VERSION "0"

NS_ :

BS_:

BU_: VCU_BeagleBone MCLeft MCRight DCU PDU BMU VCU_F7 WSBFL WSBFR WSBRL WSBRR ChargeCart
VAL_TABLE_ Vt_On_Off 1 "On" 0 "Off" ;
VAL_TABLE_ DC_Channel 4 "CHANNEL_ON_FUSE_BLOWN" 3 "CHANNEL_OFF_FUSE_BLOWN" 2 "CHANNEL_ON" 1 "CHANNEL_OFF" 0 "INVALID" ;
VAL_TABLE_ Contactor 4 "CONTACTOR_FAULT_CLOSED" 3 "CONTACTOR_FAULT_OPEN" 2 "CONTACTOR_CLOSED" 1 "CONTACTOR_OPEN" 0 "INVALID" ;
VAL_TABLE_ DCDC_State 3 "Error" 2 "On" 1 "Off" 0 "Invalid" ;
VAL_TABLE_ BMS_State 7 "Failure_Fatal" 6 "Charging" 5 "Discharge" 4 "Precharge" 3 "HV_Enable" 2 "HV_Disable" 1 "Wait_System_Up" 0 "Self_Check" ;

BO_ 3221225472 VECTOR__INDEPENDENT_SIG_MSG: 0 Vector__XXX
 SG_ Hartbeat_BMU : 0|8@1+ (1,0) [0|0] "" Vector__XXX
 SG_ Hartbeat_VCU_F7 : 0|8@1+ (1,0) [0|0] "" Vector__XXX
 SG_ Hartbeat_DCU : 0|8@1+ (1,0) [0|0] "" Vector__XXX
 SG_ Hartbeat_PDU : 0|8@1+ (1,0) [0|0] "" Vector__XXX
 SG_ Hartbeat_WSBFL : 0|8@1+ (1,0) [0|0] "" Vector__XXX
 SG_ Hartbeat_WSBFR : 0|8@1+ (1,0) [0|0] "" Vector__XXX
 SG_ Hartbeat_WSBRL : 0|8@1+ (1,0) [0|0] "" Vector__XXX
 SG_ Hartbeat_WSBRR : 0|8@1+ (1,0) [0|0] "" Vector__XXX
 SG_ Hartbeat_ChargeCart : 0|8@1+ (1,0) [0|0] "" Vector__XXX
 SG_ StateContactorPositive : 0|3@1- (1,0) [0|0] "" Vector__XXX
 SG_ StateContactorNegative : 0|3@1- (1,0) [0|0] "" Vector__XXX
 SG_ PRO_CAN_CRC : 0|8@1- (1,0) [0|0] "" Vector__XXX
 SG_ PRO_CAN_COUNT : 0|4@1- (1,0) [0|0] "" Vector__XXX
 SG_ PRO_CAN_RES : 0|4@1- (1,0) [0|0] "" Vector__XXX
 SG_ VoltageHVBusInverterRight : 0|16@1+ (1,0) [0|0] "" Vector__XXX
 SG_ CurrentHVBusInverterRight : 0|16@1+ (1,0) [0|0] "" Vector__XXX
 SG_ PRO_CAN_CRC : 0|8@1- (1,0) [0|0] "" Vector__XXX
 SG_ PRO_CAN_COUNT : 0|4@1- (1,0) [0|0] "" Vector__XXX
 SG_ PRO_CAN_RES : 0|4@1- (1,0) [0|0] "" Vector__XXX
 SG_ VoltageHVBusInverterLeft : 0|16@1+ (1,0) [0|0] "" Vector__XXX
 SG_ CurrentHVBusInverterLeft : 0|16@1+ (1,0) [0|0] "" Vector__XXX
 SG_ VoltageBatteryLV : 0|14@1+ (1,0) [0|16383] "mV" Vector__XXX

BO_ 2287209474 VCU_EM_Fault: 8 VCU_F7
 SG_ EMFaultEvent : 0|8@1+ (1,0) [0|255] ""  VCU_BeagleBone

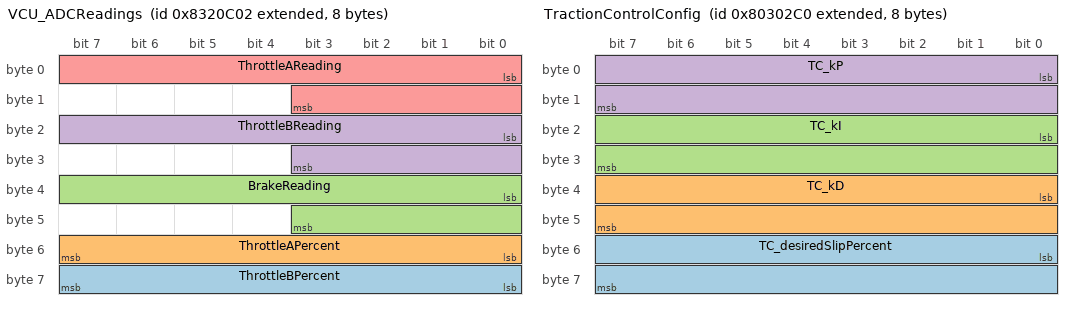
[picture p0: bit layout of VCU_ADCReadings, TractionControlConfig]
BO_ 2284981250 VCU_ADCReadings: 8 VCU_F7
 SG_ ThrottleBPercent : 56|8@1+ (0.5,0) [0|127.5] "" Vector__XXX
 SG_ ThrottleAPercent : 48|8@1+ (0.5,0) [0|127.5] "" Vector__XXX
 SG_ BrakeReading : 32|12@1+ (1,0) [0|4095] ""  VCU_BeagleBone
 SG_ ThrottleBReading : 16|12@1+ (1,0) [0|4095] ""  VCU_BeagleBone
 SG_ ThrottleAReading : 0|12@1+ (1,0) [0|4095] ""  VCU_BeagleBone

BO_ 2281898688 TractionControlConfig: 8 VCU_BeagleBone
 SG_ TC_desiredSlipPercent : 48|16@1- (0.0001,0) [-3.2768|3.2767] "percent"  VCU_F7
 SG_ TC_kD : 32|16@1+ (0.01,0) [0|655.35] ""  VCU_F7
 SG_ TC_kI : 16|16@1+ (0.01,0) [0|655.35] ""  VCU_F7
 SG_ TC_kP : 0|16@1+ (0.01,0) [0|655.35] ""  VCU_F7

BO_ 2291796994 RearWheelSpeedRADS: 8 VCU_F7
 SG_ VCU_wheelSpeed_RR : 32|32@1+ (1E-005,0) [0|42949.67295] "rads/s" Vector__XXX
 SG_ VCU_wheelSpeed_RL : 0|32@1+ (1E-005,0) [0|42949.67295] "rads/s" Vector__XXX

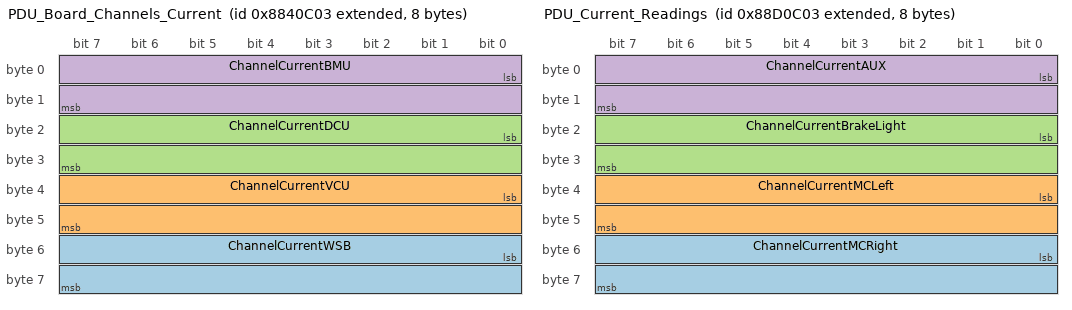
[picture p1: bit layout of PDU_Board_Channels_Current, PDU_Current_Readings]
BO_ 2290355203 PDU_Board_Channels_Current: 8 PDU
 SG_ ChannelCurrentWSB : 48|16@1+ (0.01,0) [0|0] "Amps"  VCU_BeagleBone
 SG_ ChannelCurrentVCU : 32|16@1+ (0.01,0) [0|0] "Amps"  VCU_BeagleBone
 SG_ ChannelCurrentDCU : 16|16@1+ (0.01,0) [0|0] "Amps"  VCU_BeagleBone
 SG_ ChannelCurrentBMU : 0|16@1+ (0.01,0) [0|0] "Amps"  VCU_BeagleBone

BO_ 2290945027 PDU_Current_Readings: 8 PDU
 SG_ ChannelCurrentMCRight : 48|16@1+ (0.01,0) [0|0] "Amps"  VCU_BeagleBone
 SG_ ChannelCurrentMCLeft : 32|16@1+ (0.01,0) [0|0] "Amps"  VCU_BeagleBone
 SG_ ChannelCurrentBrakeLight : 16|16@1+ (0.01,0) [0|0] "Amps"  VCU_BeagleBone
 SG_ ChannelCurrentAUX : 0|16@1+ (0.01,0) [0|0] ""  VCU_BeagleBone

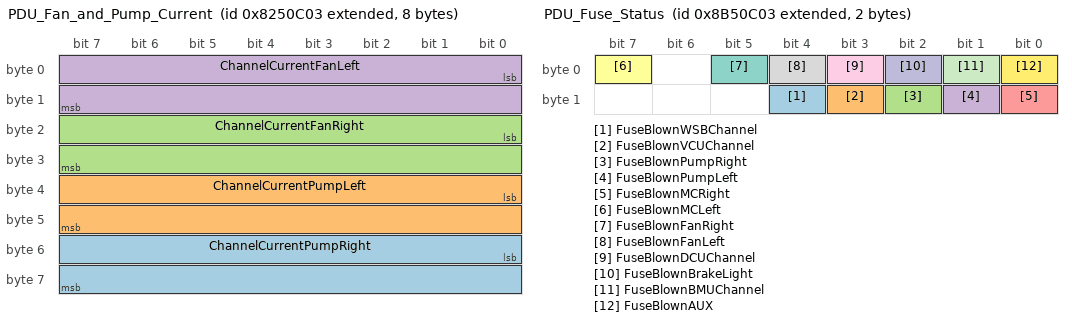
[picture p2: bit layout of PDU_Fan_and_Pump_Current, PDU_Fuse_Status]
BO_ 2284129283 PDU_Fan_and_Pump_Current: 8 PDU
 SG_ ChannelCurrentPumpRight : 48|16@1+ (0.01,0) [0|0] "Amps"  VCU_BeagleBone
 SG_ ChannelCurrentPumpLeft : 32|16@1+ (0.01,0) [0|0] "Amps"  VCU_BeagleBone
 SG_ ChannelCurrentFanRight : 16|16@1+ (0.01,0) [0|0] "Amps"  VCU_BeagleBone
 SG_ ChannelCurrentFanLeft : 0|16@1+ (0.01,0) [0|0] "Amps"  VCU_BeagleBone

BO_ 2293566467 PDU_Fuse_Status: 2 PDU
 SG_ FuseBlownWSBChannel : 12|1@1+ (1,0) [0|0] ""  VCU_BeagleBone
 SG_ FuseBlownVCUChannel : 11|1@1+ (1,0) [0|0] ""  VCU_BeagleBone
 SG_ FuseBlownPumpRight : 10|1@1+ (1,0) [0|0] ""  VCU_BeagleBone
 SG_ FuseBlownPumpLeft : 9|1@1+ (1,0) [0|0] ""  VCU_BeagleBone
 SG_ FuseBlownMCRight : 8|1@1+ (1,0) [0|0] ""  VCU_BeagleBone
 SG_ FuseBlownMCLeft : 7|1@1+ (1,0) [0|0] ""  VCU_BeagleBone
 SG_ FuseBlownFanRight : 5|1@1+ (1,0) [0|0] ""  VCU_BeagleBone
 SG_ FuseBlownFanLeft : 4|1@1+ (1,0) [0|0] ""  VCU_BeagleBone
 SG_ FuseBlownDCUChannel : 3|1@1+ (1,0) [0|0] ""  VCU_BeagleBone
 SG_ FuseBlownBrakeLight : 2|1@1+ (1,0) [0|0] ""  VCU_BeagleBone
 SG_ FuseBlownBMUChannel : 1|1@1+ (1,0) [0|0] ""  VCU_BeagleBone
 SG_ FuseBlownAUX : 0|1@1+ (1,0) [0|0] ""  VCU_BeagleBone

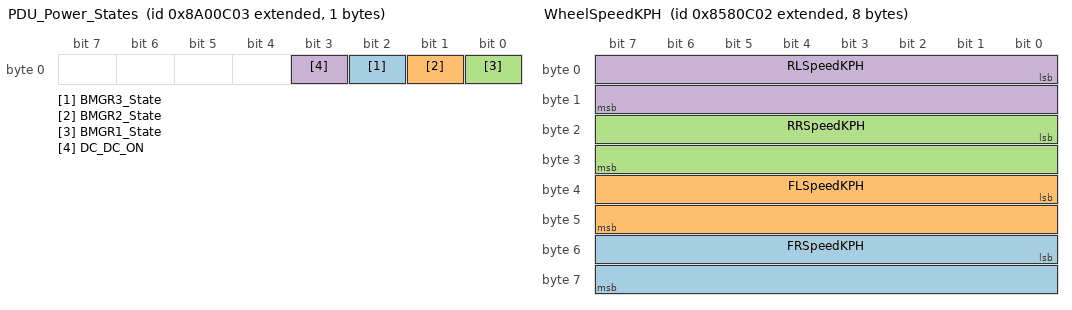
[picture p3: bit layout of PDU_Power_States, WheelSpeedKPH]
BO_ 2292190211 PDU_Power_States: 1 PDU
 SG_ BMGR3_State : 2|1@1+ (1,0) [0|0] ""  VCU_BeagleBone
 SG_ BMGR2_State : 1|1@1+ (1,0) [0|0] ""  VCU_BeagleBone
 SG_ BMGR1_State : 0|1@1+ (1,0) [0|0] ""  VCU_BeagleBone
 SG_ DC_DC_ON : 3|1@1+ (1,0) [0|0] ""  VCU_BeagleBone

BO_ 2287471618 WheelSpeedKPH: 8 VCU_F7
 SG_ FRSpeedKPH : 48|16@1- (0.04,0) [-1310.72|1310.68] "km/h" Vector__XXX
 SG_ FLSpeedKPH : 32|16@1- (0.04,0) [-1310.72|1310.68] "km/h" Vector__XXX
 SG_ RRSpeedKPH : 16|16@1- (0.04,0) [-1310.72|1310.68] "kph"  VCU_BeagleBone
 SG_ RLSpeedKPH : 0|16@1- (0.04,0) [-1310.72|1310.68] "kph"  VCU_BeagleBone

BO_ 2214986495 UartOverCanRx: 4 PDU
 SG_ UartOverCanRX : 0|32@1- (1,0) [0|4294967295] ""  VCU_BeagleBone

BO_ 2215051010 UartOverCanTx: 1 VCU_BeagleBone
 SG_ UartOverCanTX : 0|8@1- (1,0) [0|0] ""  VCU_F7,WSBRR,WSBRL,WSBFR,WSBFL,BMU,DCU,PDU

BO_ 2214985474 UartOverCanConfig: 1 VCU_BeagleBone
 SG_ UartOverCanConfigSignal : 0|8@1- (1,0) [0|0] ""  VCU_F7,WSBRR,WSBRL,WSBFR,WSBFL,PDU,DCU,BMU

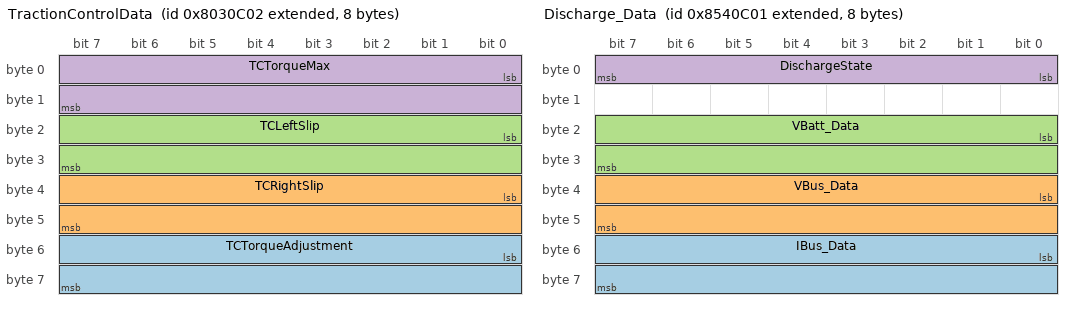
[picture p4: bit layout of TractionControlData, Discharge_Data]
BO_ 2281901058 TractionControlData: 8 VCU_F7
 SG_ TCTorqueAdjustment : 48|16@1- (0.01,0) [-327.68|327.67] "" Vector__XXX
 SG_ TCRightSlip : 32|16@1- (0.003,0) [-98.304|98.301] "percent" Vector__XXX
 SG_ TCLeftSlip : 16|16@1- (0.003,0) [-98.304|98.301] "percent" Vector__XXX
 SG_ TCTorqueMax : 0|16@1+ (0.001,0) [0|65.535] "Nm"  VCU_BeagleBone

BO_ 2215641611 WSBRR_Sensors: 8 WSBRR
 SG_ RR_WheelDistance : 0|32@1+ (1,0) [0|4294967295] "mm"  VCU_BeagleBone

BO_ 2215641610 WSBRL_Sensors: 8 WSBRL
 SG_ RL_WheelDistance : 0|32@1+ (1,0) [0|4294967295] "mm"  VCU_BeagleBone

BO_ 2215641609 WSBFR_Sensors: 8 WSBFR
 SG_ FR_WheelDistance : 0|32@1+ (1,0) [0|4294967295] "mm"  VCU_BeagleBone
 SG_ FR_Speed_RAD_S : 32|16@1- (0.0625,0) [0|4095.9375] "rad/s"  VCU_F7,VCU_BeagleBone

BO_ 2215641608 WSBFL_Sensors: 8 WSBFL
 SG_ FL_WheelDistance : 0|32@1+ (1,0) [0|4294967295] "mm"  VCU_BeagleBone
 SG_ FL_Speed_RAD_S : 32|16@1- (0.0625,0) [-2048|2047.9375] "rad/s"  VCU_F7,VCU_BeagleBone

BO_ 2281835521 BMU_BatteryChecks: 8 BMU
 SG_ BatteryTaskFailure : 0|8@1+ (1,0) [0|0] "" Vector__XXX

BO_ 2281769985 BMU_AmsVBatt: 8 BMU
 SG_ AMS_PackVoltage : 0|16@1+ (0.01,0) [0|655.35] ""  VCU_BeagleBone

BO_ 2282884097 BMU_FanPeriod: 8 BMU
 SG_ FanPeriod : 0|8@1- (1,0) [0|0] ""  VCU_BeagleBone

BO_ 2295598081 PrechargeState: 8 BMU
 SG_ PrechargeState : 0|8@1+ (1,0) [0|0] ""  VCU_BeagleBone

BO_ 2287209473 Discharge_Data: 8 BMU
 SG_ IBus_Data : 48|16@1- (1,0) [0|0] "" Vector__XXX
 SG_ VBus_Data : 32|16@1+ (1,0) [0|0] "" Vector__XXX
 SG_ VBatt_Data : 16|16@1+ (0.01,0) [0|655.35] "" Vector__XXX
 SG_ DischargeState : 0|8@1+ (1,0) [0|0] ""  VCU_BeagleBone

BO_ 2297236481 BMU_Interlock_Loop_Status: 8 BMU
 SG_ BMU_checkFailed : 0|8@1+ (1,0) [0|0] ""  VCU_BeagleBone

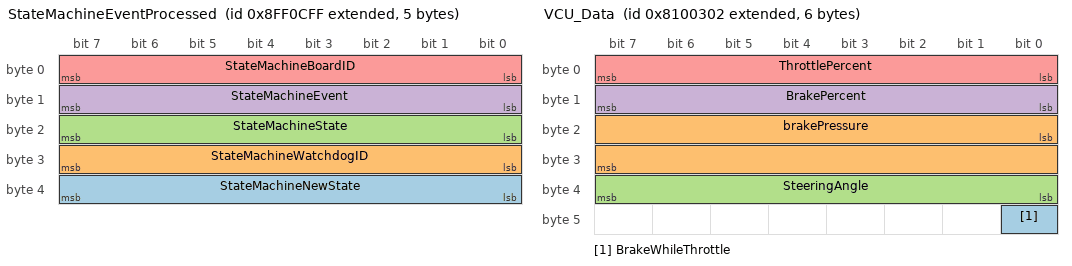
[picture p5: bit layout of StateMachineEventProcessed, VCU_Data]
BO_ 2298416383 StateMachineEventProcessed: 5 VCU_F7
 SG_ StateMachineNewState : 32|8@1+ (1,0) [0|0] "" Vector__XXX
 SG_ StateMachineWatchdogID : 24|8@1- (1,0) [0|0] ""  VCU_BeagleBone
 SG_ StateMachineState : 16|8@1- (1,0) [0|0] ""  VCU_BeagleBone
 SG_ StateMachineEvent : 8|8@1- (1,0) [0|0] ""  VCU_BeagleBone
 SG_ StateMachineBoardID : 0|8@1- (1,0) [0|0] ""  VCU_BeagleBone

BO_ 2147548939 WSBRL_DTC: 6 WSBRL
 SG_ DTC_Severity : 8|8@1- (1,0) [1|4] ""  WSBRR,WSBFR,WSBFL
 SG_ DTC_Data : 16|32@1- (1,0) [0|0] ""  WSBRR,WSBFR,WSBFL
 SG_ DTC_CODE : 0|8@1+ (1,0) [0|0] ""  WSBRR,WSBFR,WSBFL

BO_ 2147548938 WSBRR_DTC: 6 WSBRR
 SG_ DTC_Severity : 8|8@1- (1,0) [1|4] ""  WSBRL,WSBFR,WSBFL
 SG_ DTC_Data : 16|32@1- (1,0) [0|0] ""  WSBRL,WSBFR,WSBFL
 SG_ DTC_CODE : 0|8@1+ (1,0) [0|0] ""  WSBRL,WSBFR,WSBFL

BO_ 2147548937 WSBFR_DTC: 6 WSBFR
 SG_ DTC_Severity : 8|8@1- (1,0) [1|4] ""  WSBRR,WSBRL,WSBFL
 SG_ DTC_Data : 16|32@1- (1,0) [0|0] ""  WSBRR,WSBRL,WSBFL
 SG_ DTC_CODE : 0|8@1+ (1,0) [0|0] ""  WSBRR,WSBRL,WSBFL

BO_ 2147548936 WSBFL_DTC: 6 WSBFL
 SG_ DTC_Severity : 8|8@1- (1,0) [1|4] ""  WSBFR,WSBRR,WSBRL
 SG_ DTC_Data : 16|32@1- (1,0) [0|0] ""  WSBFR,WSBRR,WSBRL
 SG_ DTC_CODE : 0|8@1+ (1,0) [0|0] ""  WSBFR,WSBRR,WSBRL

BO_ 2226717697 BMU_ChargeEN_State: 8 BMU
 SG_ ChargeEN_State : 0|1@1+ (1,0) [0|0] ""  ChargeCart

BO_ 2227830532 ChargeCart_Heartbeat: 8 ChargeCart
 SG_ ChargeCart_Heartbeat_dummydata : 0|1@1- (1,0) [0|0] ""  BMU

BO_ 2551190019 LV_Bus_Measurements: 4 PDU
 SG_ CurrentBusLV : 16|16@1+ (1,0) [0|0] "mA" Vector__XXX
 SG_ VoltageBusLV : 0|14@1+ (1,0) [0|16383] "mV" Vector__XXX

BO_ 2282750722 VCU_Data: 6 VCU_F7
 SG_ BrakeWhileThrottle : 40|1@1+ (1,0) [0|1] ""  VCU_BeagleBone
 SG_ brakePressure : 16|16@1- (1,0) [0|0] ""  VCU_BeagleBone
 SG_ SteeringAngle : 32|8@1- (1,0) [0|0] "degrees" Vector__XXX
 SG_ BrakePercent : 8|8@1+ (1,0) [0|0] "percent"  PDU
 SG_ ThrottlePercent : 0|8@1+ (1,0) [0|0] "percent" Vector__XXX

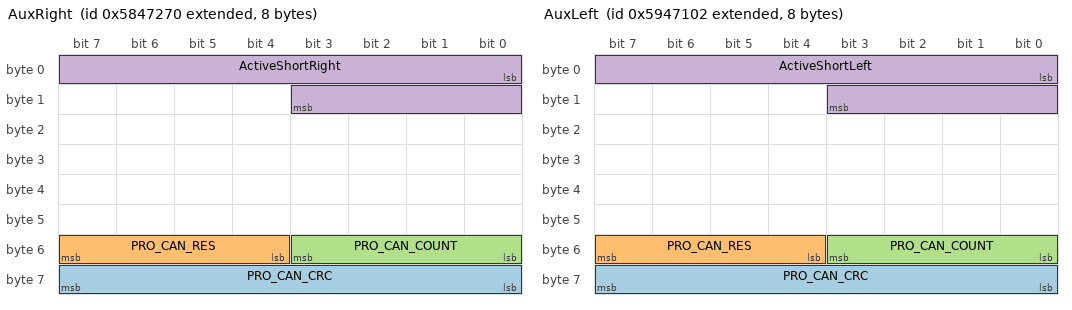
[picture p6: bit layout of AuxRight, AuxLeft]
BO_ 2240049776 AuxRight: 8 VCU_F7
 SG_ PRO_CAN_CRC : 56|8@1+ (1,0) [0|0] "" Vector__XXX
 SG_ PRO_CAN_RES : 52|4@1+ (1,0) [0|0] "" Vector__XXX
 SG_ PRO_CAN_COUNT : 48|4@1+ (1,0) [0|0] "" Vector__XXX
 SG_ ActiveShortRight : 0|12@1+ (1,0) [0|0] "" Vector__XXX

BO_ 2241097986 AuxLeft: 8 VCU_F7
 SG_ PRO_CAN_CRC : 56|8@1+ (1,0) [0|0] "" Vector__XXX
 SG_ PRO_CAN_RES : 52|4@1+ (1,0) [0|0] "" Vector__XXX
 SG_ PRO_CAN_COUNT : 48|4@1+ (1,0) [0|0] "" Vector__XXX
 SG_ ActiveShortLeft : 0|12@1+ (1,0) [0|0] "" Vector__XXX

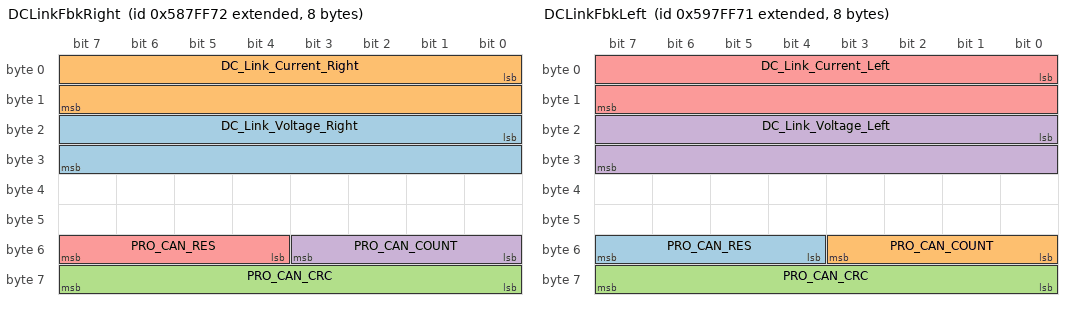
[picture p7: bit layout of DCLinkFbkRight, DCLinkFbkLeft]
BO_ 2240282482 DCLinkFbkRight: 8 MCRight
 SG_ DC_Link_Voltage_Right : 16|16@1+ (0.0625,0) [0|4095.9375] "V"  VCU_F7
 SG_ DC_Link_Current_Right : 0|16@1+ (0.0625,-128) [-128|3967.9375] "A"  VCU_F7
 SG_ PRO_CAN_CRC : 56|8@1+ (1,0) [0|0] "" Vector__XXX
 SG_ PRO_CAN_COUNT : 48|4@1+ (1,0) [0|0] "" Vector__XXX
 SG_ PRO_CAN_RES : 52|4@1+ (1,0) [0|0] "" Vector__XXX

BO_ 2241331057 DCLinkFbkLeft: 8 MCLeft
 SG_ PRO_CAN_RES : 52|4@1+ (1,0) [0|0] "" Vector__XXX
 SG_ PRO_CAN_COUNT : 48|4@1+ (1,0) [0|0] "" Vector__XXX
 SG_ PRO_CAN_CRC : 56|8@1+ (1,0) [0|0] "" Vector__XXX
 SG_ DC_Link_Voltage_Left : 16|16@1+ (0.0625,0) [0|4095.9375] "V"  VCU_F7
 SG_ DC_Link_Current_Left : 0|16@1+ (0.0625,-128) [-128|3967.9375] "A"  VCU_F7

BO_ 2214987522 VCU_EM_State: 1 VCU_F7
 SG_ EM_State : 0|1@1+ (1,0) [0|0] ""  DCU

BO_ 2214919943 DCU_Heartbeat: 1 DCU
 SG_ DCU_Heartbeat_dummydata : 0|1@1- (1,0) [0|0] ""  VCU_F7,PDU,BMU

BO_ 2214919939 PDU_Heartbeat: 1 PDU
 SG_ PDU_Heartbeat_dummydata : 0|1@1- (1,0) [0|0] ""  VCU_F7,DCU,BMU

BO_ 2214919938 VCU_F7_Heartbeat: 1 VCU_F7
 SG_ VCU_Heartbeat_dummydata : 0|1@1- (1,0) [0|0] ""  PDU,DCU,BMU

BO_ 2214919937 BMU_Heartbeat: 1 BMU
 SG_ BMU_Heartbeat_dummydata : 0|1@1- (1,0) [0|0] ""  ChargeCart,VCU_F7,PDU,DCU

BO_ 2282689025 BMU_BrakePressure: 4 BMU
 SG_ BrakePressureBMU : 0|32@1+ (0.1,0) [0|0] ""  VCU_BeagleBone

BO_ 2217082625 BMU_HV_Power_State: 1 BMU
 SG_ HV_Power_State : 0|1@1+ (1,0) [0|0] ""  ChargeCart,DCU,VCU_BeagleBone,VCU_F7,PDU

BO_ 2214855426 VCU_EM_Power_State_Request: 1 VCU_F7
 SG_ EM_Power_State_Request : 0|1@1+ (1,0) [0|0] ""  PDU

BO_ 2147548931 PDU_DTC: 6 PDU
 SG_ DTC_Severity : 8|8@1- (1,0) [1|4] ""  WSBRR,WSBRL,WSBFR,WSBFL,VCU_F7,VCU_BeagleBone,DCU,ChargeCart,BMU
 SG_ DTC_Data : 16|32@1- (1,0) [0|0] ""  WSBRR,WSBRL,WSBFR,WSBFL,VCU_F7,VCU_BeagleBone,DCU,ChargeCart,BMU
 SG_ DTC_CODE : 0|8@1+ (1,0) [0|0] ""  WSBRR,WSBRL,WSBFR,WSBFL,VCU_F7,VCU_BeagleBone,DCU,ChargeCart,BMU

BO_ 2147548935 DCU_DTC: 6 DCU
 SG_ DTC_Severity : 8|8@1- (1,0) [1|4] ""  WSBRR,WSBRL,WSBFR,WSBFL,VCU_BeagleBone,VCU_F7,PDU,ChargeCart,BMU
 SG_ DTC_Data : 16|32@1- (1,0) [0|0] ""  WSBRR,WSBRL,WSBFR,WSBFL,VCU_BeagleBone,VCU_F7,PDU,ChargeCart,BMU
 SG_ DTC_CODE : 0|8@1+ (1,0) [0|0] ""  WSBRR,WSBRL,WSBFR,WSBFL,VCU_BeagleBone,VCU_F7,PDU,ChargeCart,BMU

BO_ 2147548930 VCU_F7_DTC: 6 VCU_F7
 SG_ DTC_Severity : 8|8@1- (1,0) [1|4] ""  WSBRR,WSBRL,WSBFR,WSBFL,VCU_BeagleBone,PDU,DCU,ChargeCart,BMU
 SG_ DTC_CODE : 0|8@1+ (1,0) [0|0] ""  WSBRR,WSBRL,WSBFR,WSBFL,VCU_BeagleBone,PDU,DCU,ChargeCart,BMU
 SG_ DTC_Data : 16|32@1- (1,0) [0|0] ""  WSBRR,WSBRL,WSBFR,WSBFL,VCU_BeagleBone,PDU,DCU,ChargeCart,BMU

BO_ 2147548929 BMU_DTC: 6 BMU
 SG_ DTC_Severity : 8|8@1- (1,0) [1|4] ""  WSBRR,WSBRL,WSBFR,WSBFL,VCU_BeagleBone,VCU_F7,PDU,DCU,ChargeCart
 SG_ DTC_Data : 16|32@1- (1,0) [0|0] ""  WSBRR,WSBRL,WSBFR,WSBFL,VCU_BeagleBone,VCU_F7,PDU,DCU,ChargeCart
 SG_ DTC_CODE : 0|8@1+ (1,0) [0|0] ""  WSBRR,WSBRL,WSBFR,WSBFL,VCU_BeagleBone,VCU_F7,PDU,DCU,ChargeCart

BO_ 2147548932 ChargeCart_DTC: 6 ChargeCart
 SG_ DTC_Severity : 8|8@1- (1,0) [1|4] ""  WSBRR,WSBRL,WSBFR,WSBFL,VCU_BeagleBone,VCU_F7,PDU,DCU,BMU
 SG_ DTC_Data : 16|32@1- (1,0) [0|0] ""  WSBRR,WSBRL,WSBFR,WSBFL,VCU_BeagleBone,VCU_F7,PDU,DCU,BMU
 SG_ DTC_CODE : 0|8@1+ (1,0) [0|0] ""  WSBRR,WSBRL,WSBFR,WSBFL,VCU_BeagleBone,VCU_F7,PDU,DCU,BMU

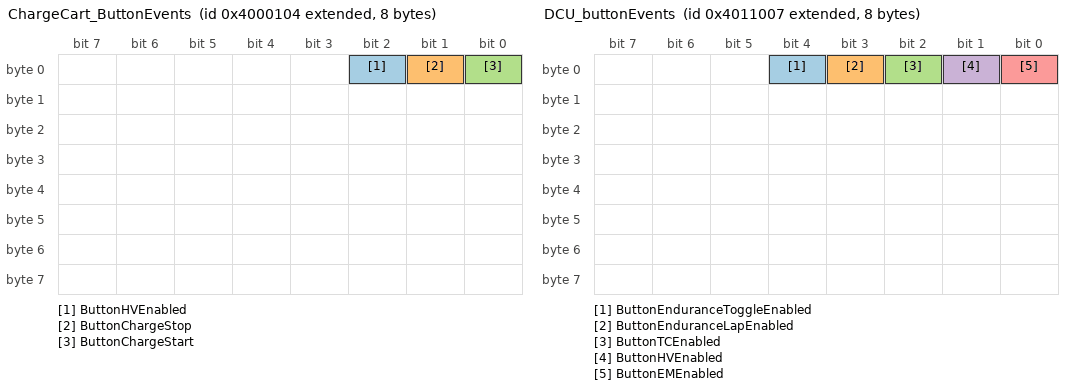
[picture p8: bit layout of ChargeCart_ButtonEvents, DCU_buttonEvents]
BO_ 2214592772 ChargeCart_ButtonEvents: 8 ChargeCart
 SG_ ButtonHVEnabled : 2|1@1- (1,0) [0|0] "bool"  BMU
 SG_ ButtonChargeStop : 1|1@1- (1,0) [0|0] "bool"  BMU,VCU_BeagleBone
 SG_ ButtonChargeStart : 0|1@1- (1,0) [0|0] "bool"  BMU,VCU_BeagleBone

BO_ 2558526465 BMU_CellVoltage: 8 BMU
 SG_ VoltageCellMuxSelect M : 0|8@1+ (1,0) [0|256] ""  ChargeCart,VCU_BeagleBone
 SG_ VoltageCell01 m0 : 8|16@1+ (0.0001,0) [0|6.5535] "V"  ChargeCart,VCU_BeagleBone
 SG_ VoltageCell02 m0 : 24|16@1+ (0.0001,0) [0|6.5535] "V"  ChargeCart,VCU_BeagleBone
 SG_ VoltageCell03 m0 : 40|16@1+ (0.0001,0) [0|6.5535] "V"  ChargeCart,VCU_BeagleBone
 SG_ VoltageCell04 m1 : 8|16@1+ (0.0001,0) [0|6.5535] "V"  ChargeCart,VCU_BeagleBone
 SG_ VoltageCell05 m1 : 24|16@1+ (0.0001,0) [0|6.5535] "V"  ChargeCart,VCU_BeagleBone
 SG_ VoltageCell06 m1 : 40|16@1+ (0.0001,0) [0|6.5535] "V"  ChargeCart,VCU_BeagleBone
 SG_ VoltageCell07 m2 : 8|16@1+ (0.0001,0) [0|6.5535] "V"  ChargeCart,VCU_BeagleBone
 SG_ VoltageCell08 m2 : 24|16@1+ (0.0001,0) [0|6.5535] "V"  ChargeCart,VCU_BeagleBone
 SG_ VoltageCell09 m2 : 40|16@1+ (0.0001,0) [0|6.5535] "V"  ChargeCart,VCU_BeagleBone
 SG_ VoltageCell10 m3 : 8|16@1+ (0.0001,0) [0|6.5535] "V"  ChargeCart,VCU_BeagleBone
 SG_ VoltageCell11 m3 : 24|16@1+ (0.0001,0) [0|6.5535] "V"  ChargeCart,VCU_BeagleBone
 SG_ VoltageCell12 m3 : 40|16@1+ (0.0001,0) [0|6.5535] "V"  ChargeCart,VCU_BeagleBone
 SG_ VoltageCell13 m4 : 8|16@1+ (0.0001,0) [0|6.5535] "V"  ChargeCart,VCU_BeagleBone
 SG_ VoltageCell14 m4 : 24|16@1+ (0.0001,0) [0|6.5535] "V"  ChargeCart,VCU_BeagleBone
 SG_ VoltageCell15 m4 : 40|16@1+ (0.0001,0) [0|6.5535] "V"  ChargeCart,VCU_BeagleBone
 SG_ VoltageCell16 m5 : 8|16@1+ (0.0001,0) [0|6.5535] "V"  ChargeCart,VCU_BeagleBone
 SG_ VoltageCell17 m5 : 24|16@1+ (0.0001,0) [0|6.5535] "V"  ChargeCart,VCU_BeagleBone
 SG_ VoltageCell18 m5 : 40|16@1+ (0.0001,0) [0|6.5535] "V"  ChargeCart,VCU_BeagleBone
 SG_ VoltageCell19 m6 : 8|16@1+ (0.0001,0) [0|6.5535] "V"  ChargeCart,VCU_BeagleBone
 SG_ VoltageCell20 m6 : 24|16@1+ (0.0001,0) [0|6.5535] "V"  ChargeCart,VCU_BeagleBone
 SG_ VoltageCell21 m6 : 40|16@1+ (0.0001,0) [0|6.5535] "V"  ChargeCart,VCU_BeagleBone
 SG_ VoltageCell22 m7 : 8|16@1+ (0.0001,0) [0|6.5535] "V"  ChargeCart,VCU_BeagleBone
 SG_ VoltageCell23 m7 : 24|16@1+ (0.0001,0) [0|6.5535] "V"  ChargeCart,VCU_BeagleBone
 SG_ VoltageCell24 m7 : 40|16@1+ (0.0001,0) [0|6.5535] "V"  ChargeCart,VCU_BeagleBone
 SG_ VoltageCell25 m8 : 8|16@1+ (0.0001,0) [0|6.5535] "V"  ChargeCart,VCU_BeagleBone
 SG_ VoltageCell26 m8 : 24|16@1+ (0.0001,0) [0|6.5535] "V"  ChargeCart,VCU_BeagleBone
 SG_ VoltageCell27 m8 : 40|16@1+ (0.0001,0) [0|6.5535] "V"  ChargeCart,VCU_BeagleBone
 SG_ VoltageCell28 m9 : 8|16@1+ (0.0001,0) [0|6.5535] "V"  ChargeCart,VCU_BeagleBone
 SG_ VoltageCell29 m9 : 24|16@1+ (0.0001,0) [0|6.5535] "V"  ChargeCart,VCU_BeagleBone
 SG_ VoltageCell30 m9 : 40|16@1+ (0.0001,0) [0|6.5535] "V"  ChargeCart,VCU_BeagleBone
 SG_ VoltageCell31 m10 : 8|16@1+ (0.0001,0) [0|6.5535] "V"  ChargeCart,VCU_BeagleBone
 SG_ VoltageCell32 m10 : 24|16@1+ (0.0001,0) [0|6.5535] "V"  ChargeCart,VCU_BeagleBone
 SG_ VoltageCell33 m10 : 40|16@1+ (0.0001,0) [0|6.5535] "V"  ChargeCart,VCU_BeagleBone
 SG_ VoltageCell34 m11 : 8|16@1+ (0.0001,0) [0|6.5535] "V"  ChargeCart,VCU_BeagleBone
 SG_ VoltageCell35 m11 : 24|16@1+ (0.0001,0) [0|6.5535] "V"  ChargeCart,VCU_BeagleBone
 SG_ VoltageCell36 m11 : 40|16@1+ (0.0001,0) [0|6.5535] "V"  ChargeCart,VCU_BeagleBone
 SG_ VoltageCell37 m12 : 8|16@1+ (0.0001,0) [0|6.5535] "V"  ChargeCart,VCU_BeagleBone
 SG_ VoltageCell38 m12 : 24|16@1+ (0.0001,0) [0|6.5535] "V"  ChargeCart,VCU_BeagleBone
 SG_ VoltageCell39 m12 : 40|16@1+ (0.0001,0) [0|6.5535] "V"  ChargeCart,VCU_BeagleBone
 SG_ VoltageCell40 m13 : 8|16@1+ (0.0001,0) [0|6.5535] "V"  ChargeCart,VCU_BeagleBone
 SG_ VoltageCell41 m13 : 24|16@1+ (0.0001,0) [0|6.5535] "V"  ChargeCart,VCU_BeagleBone
 SG_ VoltageCell42 m13 : 40|16@1+ (0.0001,0) [0|6.5535] "V"  ChargeCart,VCU_BeagleBone
 SG_ VoltageCell43 m14 : 8|16@1+ (0.0001,0) [0|6.5535] "V"  ChargeCart,VCU_BeagleBone
 SG_ VoltageCell44 m14 : 24|16@1+ (0.0001,0) [0|6.5535] "V"  ChargeCart,VCU_BeagleBone
 SG_ VoltageCell45 m14 : 40|16@1+ (0.0001,0) [0|6.5535] "V"  ChargeCart,VCU_BeagleBone
 SG_ VoltageCell46 m15 : 8|16@1+ (0.0001,0) [0|6.5535] "V"  ChargeCart,VCU_BeagleBone
 SG_ VoltageCell47 m15 : 24|16@1+ (0.0001,0) [0|6.5535] "V"  ChargeCart,VCU_BeagleBone
 SG_ VoltageCell48 m15 : 40|16@1+ (0.0001,0) [0|6.5535] "V"  ChargeCart,VCU_BeagleBone
 SG_ VoltageCell49 m16 : 8|16@1+ (0.0001,0) [0|6.5535] "V"  ChargeCart,VCU_BeagleBone
 SG_ VoltageCell50 m16 : 24|16@1+ (0.0001,0) [0|6.5535] "V"  ChargeCart,VCU_BeagleBone
 SG_ VoltageCell51 m16 : 40|16@1+ (0.0001,0) [0|6.5535] "V"  ChargeCart,VCU_BeagleBone
 SG_ VoltageCell52 m17 : 8|16@1+ (0.0001,0) [0|6.5535] "V"  ChargeCart,VCU_BeagleBone
 SG_ VoltageCell53 m17 : 24|16@1+ (0.0001,0) [0|6.5535] "V"  ChargeCart,VCU_BeagleBone
 SG_ VoltageCell54 m17 : 40|16@1+ (0.0001,0) [0|6.5535] "V"  ChargeCart,VCU_BeagleBone
 SG_ VoltageCell55 m18 : 8|16@1+ (0.0001,0) [0|6.5535] "V"  ChargeCart,VCU_BeagleBone
 SG_ VoltageCell56 m18 : 24|16@1+ (0.0001,0) [0|6.5535] "V"  ChargeCart,VCU_BeagleBone
 SG_ VoltageCell57 m18 : 40|16@1+ (0.0001,0) [0|6.5535] "V"  ChargeCart,VCU_BeagleBone
 SG_ VoltageCell58 m19 : 8|16@1+ (0.0001,0) [0|6.5535] "V"  ChargeCart,VCU_BeagleBone
 SG_ VoltageCell59 m19 : 24|16@1+ (0.0001,0) [0|6.5535] "V"  ChargeCart,VCU_BeagleBone
 SG_ VoltageCell60 m19 : 40|16@1+ (0.0001,0) [0|6.5535] "V"  ChargeCart,VCU_BeagleBone
 SG_ VoltageCell61 m20 : 8|16@1+ (0.0001,0) [0|6.5535] "V"  VCU_BeagleBone,ChargeCart
 SG_ VoltageCell62 m20 : 24|16@1+ (0.0001,0) [0|6.5535] "V"  VCU_BeagleBone,ChargeCart
 SG_ VoltageCell63 m20 : 40|16@1+ (0.0001,0) [0|6.5535] "V"  VCU_BeagleBone,ChargeCart
 SG_ VoltageCell64 m21 : 8|16@1+ (0.0001,0) [0|6.5535] "V"  VCU_BeagleBone,ChargeCart
 SG_ VoltageCell65 m21 : 24|16@1+ (0.0001,0) [0|6.5535] "V"  VCU_BeagleBone,ChargeCart
 SG_ VoltageCell66 m21 : 40|16@1+ (0.0001,0) [0|6.5535] "V"  VCU_BeagleBone,ChargeCart
 SG_ VoltageCell67 m22 : 8|16@1+ (0.0001,0) [0|6.5535] "V"  VCU_BeagleBone,ChargeCart
 SG_ VoltageCell68 m22 : 24|16@1+ (0.0001,0) [0|6.5535] "V"  VCU_BeagleBone,ChargeCart
 SG_ VoltageCell69 m22 : 40|16@1+ (0.0001,0) [0|6.5535] "V"  VCU_BeagleBone,ChargeCart
 SG_ VoltageCell70 m23 : 8|16@1+ (0.0001,0) [0|6.5535] "V"  VCU_BeagleBone,ChargeCart
 SG_ VoltageCell71 m23 : 24|16@1+ (0.0001,0) [0|6.5535] "V"  VCU_BeagleBone,ChargeCart
 SG_ VoltageCell72 m23 : 40|16@1+ (0.0001,0) [0|6.5535] "V"  VCU_BeagleBone,ChargeCart
 SG_ VoltageCell73 m24 : 8|16@1+ (0.0001,0) [0|6.5535] "V"  VCU_BeagleBone,ChargeCart
 SG_ VoltageCell74 m24 : 24|16@1+ (0.0001,0) [0|6.5535] "V"  VCU_BeagleBone,ChargeCart
 SG_ VoltageCell75 m24 : 40|16@1+ (0.0001,0) [0|6.5535] "V"  VCU_BeagleBone,ChargeCart
 SG_ VoltageCell76 m25 : 8|16@1+ (0.0001,0) [0|6.5535] "V"  VCU_BeagleBone,ChargeCart
 SG_ VoltageCell77 m25 : 24|16@1+ (0.0001,0) [0|6.5535] "V"  VCU_BeagleBone,ChargeCart
 SG_ VoltageCell78 m25 : 40|16@1+ (0.0001,0) [0|6.5535] "V"  VCU_BeagleBone,ChargeCart
 SG_ VoltageCell79 m26 : 8|16@1+ (0.0001,0) [0|6.5535] "V"  VCU_BeagleBone,ChargeCart
 SG_ VoltageCell80 m26 : 24|16@1+ (0.0001,0) [0|6.5535] "V"  VCU_BeagleBone,ChargeCart
 SG_ VoltageCell81 m26 : 40|16@1+ (0.0001,0) [0|6.5535] "V"  VCU_BeagleBone,ChargeCart
 SG_ VoltageCell82 m27 : 8|16@1+ (0.0001,0) [0|6.5535] "V"  VCU_BeagleBone,ChargeCart
 SG_ VoltageCell83 m27 : 24|16@1+ (0.0001,0) [0|6.5535] "V"  VCU_BeagleBone,ChargeCart
 SG_ VoltageCell84 m27 : 40|16@1+ (0.0001,0) [0|6.5535] "V"  VCU_BeagleBone,ChargeCart
 SG_ VoltageCell85 m28 : 8|16@1+ (0.0001,0) [0|6.5535] "V"  VCU_BeagleBone,ChargeCart
 SG_ VoltageCell86 m28 : 24|16@1+ (0.0001,0) [0|6.5535] "V"  VCU_BeagleBone,ChargeCart
 SG_ VoltageCell87 m28 : 40|16@1+ (0.0001,0) [0|6.5535] "V"  VCU_BeagleBone,ChargeCart
 SG_ VoltageCell88 m29 : 8|16@1+ (0.0001,0) [0|6.5535] "V"  VCU_BeagleBone,ChargeCart
 SG_ VoltageCell89 m29 : 24|16@1+ (0.0001,0) [0|6.5535] "V"  VCU_BeagleBone,ChargeCart
 SG_ VoltageCell90 m29 : 40|16@1+ (0.0001,0) [0|6.5535] "V"  VCU_BeagleBone,ChargeCart
 SG_ VoltageCell91 m30 : 8|16@1+ (0.0001,0) [0|6.5535] "V"  VCU_BeagleBone,ChargeCart
 SG_ VoltageCell92 m30 : 24|16@1+ (0.0001,0) [0|6.5535] "V"  VCU_BeagleBone,ChargeCart
 SG_ VoltageCell93 m30 : 40|16@1+ (0.0001,0) [0|6.5535] "V"  VCU_BeagleBone,ChargeCart
 SG_ VoltageCell94 m31 : 8|16@1+ (0.0001,0) [0|6.5535] "V"  VCU_BeagleBone,ChargeCart
 SG_ VoltageCell95 m31 : 24|16@1+ (0.0001,0) [0|6.5535] "V"  VCU_BeagleBone,ChargeCart
 SG_ VoltageCell96 m31 : 40|16@1+ (0.0001,0) [0|6.5535] "V"  VCU_BeagleBone,ChargeCart
 SG_ VoltageCell97 m32 : 8|16@1+ (0.0001,0) [0|6.5535] "V"  VCU_BeagleBone,ChargeCart
 SG_ VoltageCell98 m32 : 24|16@1+ (0.0001,0) [0|6.5535] "V"  VCU_BeagleBone,ChargeCart
 SG_ VoltageCell99 m32 : 40|16@1+ (0.0001,0) [0|6.5535] "V"  VCU_BeagleBone,ChargeCart
 SG_ VoltageCell100 m33 : 8|16@1+ (0.0001,0) [0|6.5535] "V"  VCU_BeagleBone,ChargeCart
 SG_ VoltageCell101 m33 : 24|16@1+ (0.0001,0) [0|6.5535] "V"  VCU_BeagleBone,ChargeCart
 SG_ VoltageCell102 m33 : 40|16@1+ (0.0001,0) [0|6.5535] "V"  VCU_BeagleBone,ChargeCart
 SG_ VoltageCell103 m34 : 8|16@1+ (0.0001,0) [0|6.5535] "V"  VCU_BeagleBone,ChargeCart
 SG_ VoltageCell104 m34 : 24|16@1+ (0.0001,0) [0|6.5535] "V"  VCU_BeagleBone,ChargeCart
 SG_ VoltageCell105 m34 : 40|16@1+ (0.0001,0) [0|6.5535] "V"  VCU_BeagleBone,ChargeCart
 SG_ VoltageCell106 m35 : 8|16@1+ (0.0001,0) [0|6.5535] "V"  VCU_BeagleBone,ChargeCart
 SG_ VoltageCell107 m35 : 24|16@1+ (0.0001,0) [0|6.5535] "V"  VCU_BeagleBone,ChargeCart
 SG_ VoltageCell108 m35 : 40|16@1+ (0.0001,0) [0|6.5535] "V"  VCU_BeagleBone,ChargeCart
 SG_ VoltageCell109 m36 : 8|16@1+ (0.0001,0) [0|6.5535] "V"  VCU_BeagleBone,ChargeCart
 SG_ VoltageCell110 m36 : 24|16@1+ (0.0001,0) [0|6.5535] "V"  VCU_BeagleBone,ChargeCart
 SG_ VoltageCell111 m36 : 40|16@1+ (0.0001,0) [0|6.5535] "V"  VCU_BeagleBone,ChargeCart
 SG_ VoltageCell112 m37 : 8|16@1+ (0.0001,0) [0|6.5535] "V"  VCU_BeagleBone,ChargeCart
 SG_ VoltageCell113 m37 : 24|16@1+ (0.0001,0) [0|6.5535] "V"  VCU_BeagleBone,ChargeCart
 SG_ VoltageCell114 m37 : 40|16@1+ (0.0001,0) [0|6.5535] "V"  VCU_BeagleBone,ChargeCart
 SG_ VoltageCell115 m38 : 8|16@1+ (0.0001,0) [0|6.5535] "V"  VCU_BeagleBone,ChargeCart
 SG_ VoltageCell116 m38 : 24|16@1+ (0.0001,0) [0|6.5535] "V"  VCU_BeagleBone,ChargeCart
 SG_ VoltageCell117 m38 : 40|16@1+ (0.0001,0) [0|6.5535] "V"  VCU_BeagleBone,ChargeCart
 SG_ VoltageCell118 m39 : 8|16@1+ (0.0001,0) [0|6.5535] "V"  VCU_BeagleBone,ChargeCart
 SG_ VoltageCell119 m39 : 24|16@1+ (0.0001,0) [0|6.5535] "V"  VCU_BeagleBone,ChargeCart
 SG_ VoltageCell120 m39 : 40|16@1+ (0.0001,0) [0|6.5535] "V"  VCU_BeagleBone,ChargeCart
 SG_ VoltageCell121 m40 : 8|16@1+ (0.0001,0) [0|6.5535] "V"  VCU_BeagleBone,ChargeCart
 SG_ VoltageCell122 m40 : 24|16@1+ (0.0001,0) [0|6.5535] "V"  VCU_BeagleBone,ChargeCart
 SG_ VoltageCell123 m40 : 40|16@1+ (0.0001,0) [0|6.5535] "V"  VCU_BeagleBone,ChargeCart
 SG_ VoltageCell124 m41 : 8|16@1+ (0.0001,0) [0|6.5535] "V"  VCU_BeagleBone,ChargeCart
 SG_ VoltageCell125 m41 : 24|16@1+ (0.0001,0) [0|6.5535] "V"  VCU_BeagleBone,ChargeCart
 SG_ VoltageCell126 m41 : 40|16@1+ (0.0001,0) [0|6.5535] "V"  VCU_BeagleBone,ChargeCart
 SG_ VoltageCell127 m42 : 8|16@1+ (0.0001,0) [0|6.5535] "V"  VCU_BeagleBone,ChargeCart
 SG_ VoltageCell128 m42 : 24|16@1+ (0.0001,0) [0|6.5535] "V"  VCU_BeagleBone,ChargeCart
 SG_ VoltageCell129 m42 : 40|16@1+ (0.0001,0) [0|6.5535] "V"  VCU_BeagleBone,ChargeCart
 SG_ VoltageCell130 m43 : 8|16@1+ (0.0001,0) [0|6.5535] "V"  VCU_BeagleBone,ChargeCart
 SG_ VoltageCell131 m43 : 24|16@1+ (0.0001,0) [0|6.5535] "V"  VCU_BeagleBone,ChargeCart
 SG_ VoltageCell132 m43 : 40|16@1+ (0.0001,0) [0|6.5535] "V"  VCU_BeagleBone,ChargeCart
 SG_ VoltageCell133 m44 : 8|16@1+ (0.0001,0) [0|6.5535] "V"  VCU_BeagleBone,ChargeCart
 SG_ VoltageCell134 m44 : 24|16@1+ (0.0001,0) [0|6.5535] "V"  VCU_BeagleBone,ChargeCart
 SG_ VoltageCell135 m44 : 40|16@1+ (0.0001,0) [0|6.5535] "V"  VCU_BeagleBone,ChargeCart
 SG_ VoltageCell136 m45 : 8|16@1+ (0.0001,0) [0|6.5535] "V"  VCU_BeagleBone,ChargeCart
 SG_ VoltageCell137 m45 : 24|16@1+ (0.0001,0) [0|6.5535] "V"  VCU_BeagleBone,ChargeCart
 SG_ VoltageCell138 m45 : 40|16@1+ (0.0001,0) [0|6.5535] "V"  VCU_BeagleBone,ChargeCart
 SG_ VoltageCell139 m46 : 8|16@1+ (0.0001,0) [0|6.5535] "V"  VCU_BeagleBone,ChargeCart
 SG_ VoltageCell140 m46 : 24|16@1+ (0.0001,0) [0|6.5535] "V"  VCU_BeagleBone,ChargeCart

BO_ 2558788609 BMU_CellVoltage_Adjusted: 8 BMU
 SG_ AdjustedVoltageCellMuxSelect M : 0|8@1+ (1,0) [0|256] ""  VCU_BeagleBone
 SG_ AdjustedVoltageCell01 m0 : 8|16@1+ (0.0001,0) [0|6.5535] "V"  VCU_BeagleBone
 SG_ AdjustedVoltageCell02 m0 : 24|16@1+ (0.0001,0) [0|6.5535] "V"  VCU_BeagleBone
 SG_ AdjustedVoltageCell03 m0 : 40|16@1+ (0.0001,0) [0|6.5535] "V"  VCU_BeagleBone
 SG_ AdjustedVoltageCell04 m1 : 8|16@1+ (0.0001,0) [0|6.5535] "V"  VCU_BeagleBone
 SG_ AdjustedVoltageCell05 m1 : 24|16@1+ (0.0001,0) [0|6.5535] "V"  VCU_BeagleBone
 SG_ AdjustedVoltageCell06 m1 : 40|16@1+ (0.0001,0) [0|6.5535] "V"  VCU_BeagleBone
 SG_ AdjustedVoltageCell07 m2 : 8|16@1+ (0.0001,0) [0|6.5535] "V"  VCU_BeagleBone
 SG_ AdjustedVoltageCell08 m2 : 24|16@1+ (0.0001,0) [0|6.5535] "V"  VCU_BeagleBone
 SG_ AdjustedVoltageCell09 m2 : 40|16@1+ (0.0001,0) [0|6.5535] "V"  VCU_BeagleBone
 SG_ AdjustedVoltageCell10 m3 : 8|16@1+ (0.0001,0) [0|6.5535] "V"  VCU_BeagleBone
 SG_ AdjustedVoltageCell11 m3 : 24|16@1+ (0.0001,0) [0|6.5535] "V"  VCU_BeagleBone
 SG_ AdjustedVoltageCell12 m3 : 40|16@1+ (0.0001,0) [0|6.5535] "V"  VCU_BeagleBone
 SG_ AdjustedVoltageCell13 m4 : 8|16@1+ (0.0001,0) [0|6.5535] "V"  VCU_BeagleBone
 SG_ AdjustedVoltageCell14 m4 : 24|16@1+ (0.0001,0) [0|6.5535] "V"  VCU_BeagleBone
 SG_ AdjustedVoltageCell15 m4 : 40|16@1+ (0.0001,0) [0|6.5535] "V"  VCU_BeagleBone
 SG_ AdjustedVoltageCell16 m5 : 8|16@1+ (0.0001,0) [0|6.5535] "V"  VCU_BeagleBone
 SG_ AdjustedVoltageCell17 m5 : 24|16@1+ (0.0001,0) [0|6.5535] "V"  VCU_BeagleBone
 SG_ AdjustedVoltageCell18 m5 : 40|16@1+ (0.0001,0) [0|6.5535] "V"  VCU_BeagleBone
 SG_ AdjustedVoltageCell19 m6 : 8|16@1+ (0.0001,0) [0|6.5535] "V"  VCU_BeagleBone
 SG_ AdjustedVoltageCell20 m6 : 24|16@1+ (0.0001,0) [0|6.5535] "V"  VCU_BeagleBone
 SG_ AdjustedVoltageCell21 m6 : 40|16@1+ (0.0001,0) [0|6.5535] "V"  VCU_BeagleBone
 SG_ AdjustedVoltageCell22 m7 : 8|16@1+ (0.0001,0) [0|6.5535] "V"  VCU_BeagleBone
 SG_ AdjustedVoltageCell23 m7 : 24|16@1+ (0.0001,0) [0|6.5535] "V"  VCU_BeagleBone
 SG_ AdjustedVoltageCell24 m7 : 40|16@1+ (0.0001,0) [0|6.5535] "V"  VCU_BeagleBone
 SG_ AdjustedVoltageCell25 m8 : 8|16@1+ (0.0001,0) [0|6.5535] "V"  VCU_BeagleBone
 SG_ AdjustedVoltageCell26 m8 : 24|16@1+ (0.0001,0) [0|6.5535] "V"  VCU_BeagleBone
 SG_ AdjustedVoltageCell27 m8 : 40|16@1+ (0.0001,0) [0|6.5535] "V"  VCU_BeagleBone
 SG_ AdjustedVoltageCell28 m9 : 8|16@1+ (0.0001,0) [0|6.5535] "V"  VCU_BeagleBone
 SG_ AdjustedVoltageCell29 m9 : 24|16@1+ (0.0001,0) [0|6.5535] "V"  VCU_BeagleBone
 SG_ AdjustedVoltageCell30 m9 : 40|16@1+ (0.0001,0) [0|6.5535] "V"  VCU_BeagleBone
 SG_ AdjustedVoltageCell31 m10 : 8|16@1+ (0.0001,0) [0|6.5535] "V"  VCU_BeagleBone
 SG_ AdjustedVoltageCell32 m10 : 24|16@1+ (0.0001,0) [0|6.5535] "V"  VCU_BeagleBone
 SG_ AdjustedVoltageCell33 m10 : 40|16@1+ (0.0001,0) [0|6.5535] "V"  VCU_BeagleBone
 SG_ AdjustedVoltageCell34 m11 : 8|16@1+ (0.0001,0) [0|6.5535] "V"  VCU_BeagleBone
 SG_ AdjustedVoltageCell35 m11 : 24|16@1+ (0.0001,0) [0|6.5535] "V"  VCU_BeagleBone
 SG_ AdjustedVoltageCell36 m11 : 40|16@1+ (0.0001,0) [0|6.5535] "V"  VCU_BeagleBone
 SG_ AdjustedVoltageCell37 m12 : 8|16@1+ (0.0001,0) [0|6.5535] "V"  VCU_BeagleBone
 SG_ AdjustedVoltageCell38 m12 : 24|16@1+ (0.0001,0) [0|6.5535] "V"  VCU_BeagleBone
 SG_ AdjustedVoltageCell39 m12 : 40|16@1+ (0.0001,0) [0|6.5535] "V"  VCU_BeagleBone
 SG_ AdjustedVoltageCell40 m13 : 8|16@1+ (0.0001,0) [0|6.5535] "V"  VCU_BeagleBone
 SG_ AdjustedVoltageCell41 m13 : 24|16@1+ (0.0001,0) [0|6.5535] "V"  VCU_BeagleBone
 SG_ AdjustedVoltageCell42 m13 : 40|16@1+ (0.0001,0) [0|6.5535] "V"  VCU_BeagleBone
 SG_ AdjustedVoltageCell43 m14 : 8|16@1+ (0.0001,0) [0|6.5535] "V"  VCU_BeagleBone
 SG_ AdjustedVoltageCell44 m14 : 24|16@1+ (0.0001,0) [0|6.5535] "V"  VCU_BeagleBone
 SG_ AdjustedVoltageCell45 m14 : 40|16@1+ (0.0001,0) [0|6.5535] "V"  VCU_BeagleBone
 SG_ AdjustedVoltageCell46 m15 : 8|16@1+ (0.0001,0) [0|6.5535] "V"  VCU_BeagleBone
 SG_ AdjustedVoltageCell47 m15 : 24|16@1+ (0.0001,0) [0|6.5535] "V"  VCU_BeagleBone
 SG_ AdjustedVoltageCell48 m15 : 40|16@1+ (0.0001,0) [0|6.5535] "V"  VCU_BeagleBone
 SG_ AdjustedVoltageCell49 m16 : 8|16@1+ (0.0001,0) [0|6.5535] "V"  VCU_BeagleBone
 SG_ AdjustedVoltageCell50 m16 : 24|16@1+ (0.0001,0) [0|6.5535] "V"  VCU_BeagleBone
 SG_ AdjustedVoltageCell51 m16 : 40|16@1+ (0.0001,0) [0|6.5535] "V"  VCU_BeagleBone
 SG_ AdjustedVoltageCell52 m17 : 8|16@1+ (0.0001,0) [0|6.5535] "V"  VCU_BeagleBone
 SG_ AdjustedVoltageCell53 m17 : 24|16@1+ (0.0001,0) [0|6.5535] "V"  VCU_BeagleBone
 SG_ AdjustedVoltageCell54 m17 : 40|16@1+ (0.0001,0) [0|6.5535] "V"  VCU_BeagleBone
 SG_ AdjustedVoltageCell55 m18 : 8|16@1+ (0.0001,0) [0|6.5535] "V"  VCU_BeagleBone
 SG_ AdjustedVoltageCell56 m18 : 24|16@1+ (0.0001,0) [0|6.5535] "V"  VCU_BeagleBone
 SG_ AdjustedVoltageCell57 m18 : 40|16@1+ (0.0001,0) [0|6.5535] "V"  VCU_BeagleBone
 SG_ AdjustedVoltageCell58 m19 : 8|16@1+ (0.0001,0) [0|6.5535] "V"  VCU_BeagleBone
 SG_ AdjustedVoltageCell59 m19 : 24|16@1+ (0.0001,0) [0|6.5535] "V"  VCU_BeagleBone
 SG_ AdjustedVoltageCell60 m19 : 40|16@1+ (0.0001,0) [0|6.5535] "V"  VCU_BeagleBone
 SG_ AdjustedVoltageCell61 m20 : 8|16@1+ (0.0001,0) [0|6.5535] "V"  VCU_BeagleBone
 SG_ AdjustedVoltageCell62 m20 : 24|16@1+ (0.0001,0) [0|6.5535] "V"  VCU_BeagleBone
 SG_ AdjustedVoltageCell63 m20 : 40|16@1+ (0.0001,0) [0|6.5535] "V"  VCU_BeagleBone
 SG_ AdjustedVoltageCell64 m21 : 8|16@1+ (0.0001,0) [0|6.5535] "V"  VCU_BeagleBone
 SG_ AdjustedVoltageCell65 m21 : 24|16@1+ (0.0001,0) [0|6.5535] "V"  VCU_BeagleBone
 SG_ AdjustedVoltageCell66 m21 : 40|16@1+ (0.0001,0) [0|6.5535] "V"  VCU_BeagleBone
 SG_ AdjustedVoltageCell67 m22 : 8|16@1+ (0.0001,0) [0|6.5535] "V"  VCU_BeagleBone
 SG_ AdjustedVoltageCell68 m22 : 24|16@1+ (0.0001,0) [0|6.5535] "V"  VCU_BeagleBone
 SG_ AdjustedVoltageCell69 m22 : 40|16@1+ (0.0001,0) [0|6.5535] "V"  VCU_BeagleBone
 SG_ AdjustedVoltageCell70 m23 : 8|16@1+ (0.0001,0) [0|6.5535] "V"  VCU_BeagleBone
 SG_ AdjustedVoltageCell71 m23 : 24|16@1+ (0.0001,0) [0|6.5535] "V"  VCU_BeagleBone
 SG_ AdjustedVoltageCell72 m23 : 40|16@1+ (0.0001,0) [0|6.5535] "V"  VCU_BeagleBone
 SG_ AdjustedVoltageCell73 m24 : 8|16@1+ (0.0001,0) [0|6.5535] "V"  VCU_BeagleBone
 SG_ AdjustedVoltageCell74 m24 : 24|16@1+ (0.0001,0) [0|6.5535] "V"  VCU_BeagleBone
 SG_ AdjustedVoltageCell75 m24 : 40|16@1+ (0.0001,0) [0|6.5535] "V"  VCU_BeagleBone
 SG_ AdjustedVoltageCell76 m25 : 8|16@1+ (0.0001,0) [0|6.5535] "V"  VCU_BeagleBone
 SG_ AdjustedVoltageCell77 m25 : 24|16@1+ (0.0001,0) [0|6.5535] "V"  VCU_BeagleBone
 SG_ AdjustedVoltageCell78 m25 : 40|16@1+ (0.0001,0) [0|6.5535] "V"  VCU_BeagleBone
 SG_ AdjustedVoltageCell79 m26 : 8|16@1+ (0.0001,0) [0|6.5535] "V"  VCU_BeagleBone
 SG_ AdjustedVoltageCell80 m26 : 24|16@1+ (0.0001,0) [0|6.5535] "V"  VCU_BeagleBone
 SG_ AdjustedVoltageCell81 m26 : 40|16@1+ (0.0001,0) [0|6.5535] "V"  VCU_BeagleBone
 SG_ AdjustedVoltageCell82 m27 : 8|16@1+ (0.0001,0) [0|6.5535] "V"  VCU_BeagleBone
 SG_ AdjustedVoltageCell83 m27 : 24|16@1+ (0.0001,0) [0|6.5535] "V"  VCU_BeagleBone
 SG_ AdjustedVoltageCell84 m27 : 40|16@1+ (0.0001,0) [0|6.5535] "V"  VCU_BeagleBone
 SG_ AdjustedVoltageCell85 m28 : 8|16@1+ (0.0001,0) [0|6.5535] "V"  VCU_BeagleBone
 SG_ AdjustedVoltageCell86 m28 : 24|16@1+ (0.0001,0) [0|6.5535] "V"  VCU_BeagleBone
 SG_ AdjustedVoltageCell87 m28 : 40|16@1+ (0.0001,0) [0|6.5535] "V"  VCU_BeagleBone
 SG_ AdjustedVoltageCell88 m29 : 8|16@1+ (0.0001,0) [0|6.5535] "V"  VCU_BeagleBone
 SG_ AdjustedVoltageCell89 m29 : 24|16@1+ (0.0001,0) [0|6.5535] "V"  VCU_BeagleBone
 SG_ AdjustedVoltageCell90 m29 : 40|16@1+ (0.0001,0) [0|6.5535] "V"  VCU_BeagleBone
 SG_ AdjustedVoltageCell91 m30 : 8|16@1+ (0.0001,0) [0|6.5535] "V"  VCU_BeagleBone
 SG_ AdjustedVoltageCell92 m30 : 24|16@1+ (0.0001,0) [0|6.5535] "V"  VCU_BeagleBone
 SG_ AdjustedVoltageCell93 m30 : 40|16@1+ (0.0001,0) [0|6.5535] "V"  VCU_BeagleBone
 SG_ AdjustedVoltageCell94 m31 : 8|16@1+ (0.0001,0) [0|6.5535] "V"  VCU_BeagleBone
 SG_ AdjustedVoltageCell95 m31 : 24|16@1+ (0.0001,0) [0|6.5535] "V"  VCU_BeagleBone
 SG_ AdjustedVoltageCell96 m31 : 40|16@1+ (0.0001,0) [0|6.5535] "V"  VCU_BeagleBone
 SG_ AdjustedVoltageCell97 m32 : 8|16@1+ (0.0001,0) [0|6.5535] "V"  VCU_BeagleBone
 SG_ AdjustedVoltageCell98 m32 : 24|16@1+ (0.0001,0) [0|6.5535] "V"  VCU_BeagleBone
 SG_ AdjustedVoltageCell99 m32 : 40|16@1+ (0.0001,0) [0|6.5535] "V"  VCU_BeagleBone
 SG_ AdjustedVoltageCell100 m33 : 8|16@1+ (0.0001,0) [0|6.5535] "V"  VCU_BeagleBone
 SG_ AdjustedVoltageCell101 m33 : 24|16@1+ (0.0001,0) [0|6.5535] "V"  VCU_BeagleBone
 SG_ AdjustedVoltageCell102 m33 : 40|16@1+ (0.0001,0) [0|6.5535] "V"  VCU_BeagleBone
 SG_ AdjustedVoltageCell103 m34 : 8|16@1+ (0.0001,0) [0|6.5535] "V"  VCU_BeagleBone
 SG_ AdjustedVoltageCell104 m34 : 24|16@1+ (0.0001,0) [0|6.5535] "V"  VCU_BeagleBone
 SG_ AdjustedVoltageCell105 m34 : 40|16@1+ (0.0001,0) [0|6.5535] "V"  VCU_BeagleBone
 SG_ AdjustedVoltageCell106 m35 : 8|16@1+ (0.0001,0) [0|6.5535] "V"  VCU_BeagleBone
 SG_ AdjustedVoltageCell107 m35 : 24|16@1+ (0.0001,0) [0|6.5535] "V"  VCU_BeagleBone
 SG_ AdjustedVoltageCell108 m35 : 40|16@1+ (0.0001,0) [0|6.5535] "V"  VCU_BeagleBone
 SG_ AdjustedVoltageCell109 m36 : 8|16@1+ (0.0001,0) [0|6.5535] "V"  VCU_BeagleBone
 SG_ AdjustedVoltageCell110 m36 : 24|16@1+ (0.0001,0) [0|6.5535] "V"  VCU_BeagleBone
 SG_ AdjustedVoltageCell111 m36 : 40|16@1+ (0.0001,0) [0|6.5535] "V"  VCU_BeagleBone
 SG_ AdjustedVoltageCell112 m37 : 8|16@1+ (0.0001,0) [0|6.5535] "V"  VCU_BeagleBone
 SG_ AdjustedVoltageCell113 m37 : 24|16@1+ (0.0001,0) [0|6.5535] "V"  VCU_BeagleBone
 SG_ AdjustedVoltageCell114 m37 : 40|16@1+ (0.0001,0) [0|6.5535] "V"  VCU_BeagleBone
 SG_ AdjustedVoltageCell115 m38 : 8|16@1+ (0.0001,0) [0|6.5535] "V"  VCU_BeagleBone
 SG_ AdjustedVoltageCell116 m38 : 24|16@1+ (0.0001,0) [0|6.5535] "V"  VCU_BeagleBone
 SG_ AdjustedVoltageCell117 m38 : 40|16@1+ (0.0001,0) [0|6.5535] "V"  VCU_BeagleBone
 SG_ AdjustedVoltageCell118 m39 : 8|16@1+ (0.0001,0) [0|6.5535] "V"  VCU_BeagleBone
 SG_ AdjustedVoltageCell119 m39 : 24|16@1+ (0.0001,0) [0|6.5535] "V"  VCU_BeagleBone
 SG_ AdjustedVoltageCell120 m39 : 40|16@1+ (0.0001,0) [0|6.5535] "V"  VCU_BeagleBone
 SG_ AdjustedVoltageCell121 m40 : 8|16@1+ (0.0001,0) [0|6.5535] "V"  VCU_BeagleBone
 SG_ AdjustedVoltageCell122 m40 : 24|16@1+ (0.0001,0) [0|6.5535] "V"  VCU_BeagleBone
 SG_ AdjustedVoltageCell123 m40 : 40|16@1+ (0.0001,0) [0|6.5535] "V"  VCU_BeagleBone
 SG_ AdjustedVoltageCell124 m41 : 8|16@1+ (0.0001,0) [0|6.5535] "V"  VCU_BeagleBone
 SG_ AdjustedVoltageCell125 m41 : 24|16@1+ (0.0001,0) [0|6.5535] "V"  VCU_BeagleBone
 SG_ AdjustedVoltageCell126 m41 : 40|16@1+ (0.0001,0) [0|6.5535] "V"  VCU_BeagleBone
 SG_ AdjustedVoltageCell127 m42 : 8|16@1+ (0.0001,0) [0|6.5535] "V"  VCU_BeagleBone
 SG_ AdjustedVoltageCell128 m42 : 24|16@1+ (0.0001,0) [0|6.5535] "V"  VCU_BeagleBone
 SG_ AdjustedVoltageCell129 m42 : 40|16@1+ (0.0001,0) [0|6.5535] "V"  VCU_BeagleBone
 SG_ AdjustedVoltageCell130 m43 : 8|16@1+ (0.0001,0) [0|6.5535] "V"  VCU_BeagleBone
 SG_ AdjustedVoltageCell131 m43 : 24|16@1+ (0.0001,0) [0|6.5535] "V"  VCU_BeagleBone
 SG_ AdjustedVoltageCell132 m43 : 40|16@1+ (0.0001,0) [0|6.5535] "V"  VCU_BeagleBone
 SG_ AdjustedVoltageCell133 m44 : 8|16@1+ (0.0001,0) [0|6.5535] "V"  VCU_BeagleBone
 SG_ AdjustedVoltageCell134 m44 : 24|16@1+ (0.0001,0) [0|6.5535] "V"  VCU_BeagleBone
 SG_ AdjustedVoltageCell135 m44 : 40|16@1+ (0.0001,0) [0|6.5535] "V"  VCU_BeagleBone
 SG_ AdjustedVoltageCell136 m45 : 8|16@1+ (0.0001,0) [0|6.5535] "V"  VCU_BeagleBone
 SG_ AdjustedVoltageCell137 m45 : 24|16@1+ (0.0001,0) [0|6.5535] "V"  VCU_BeagleBone
 SG_ AdjustedVoltageCell138 m45 : 40|16@1+ (0.0001,0) [0|6.5535] "V"  VCU_BeagleBone
 SG_ AdjustedVoltageCell139 m46 : 8|16@1+ (0.0001,0) [0|6.5535] "V"  VCU_BeagleBone
 SG_ AdjustedVoltageCell140 m46 : 24|16@1+ (0.0001,0) [0|6.5535] "V"  VCU_BeagleBone

BO_ 2562720769 BMU_ChannelTemp: 8 BMU
 SG_ TempChannelMuxSelect M : 0|8@1+ (1,0) [0|256] ""  ChargeCart,VCU_BeagleBone
 SG_ TempChannel01 m0 : 8|16@1+ (0.01,-100) [-100|555.35] "C"  ChargeCart,VCU_BeagleBone
 SG_ TempChannel02 m0 : 24|16@1+ (0.01,-100) [-100|555.35] "C"  ChargeCart,VCU_BeagleBone
 SG_ TempChannel03 m0 : 40|16@1+ (0.01,-100) [-100|555.35] "C"  ChargeCart,VCU_BeagleBone
 SG_ TempChannel04 m1 : 8|16@1+ (0.01,-100) [-100|555.35] "C"  ChargeCart,VCU_BeagleBone
 SG_ TempChannel05 m1 : 24|16@1+ (0.01,-100) [-100|555.35] "C"  ChargeCart,VCU_BeagleBone
 SG_ TempChannel06 m1 : 40|16@1+ (0.01,-100) [-100|555.35] "C"  ChargeCart,VCU_BeagleBone
 SG_ TempChannel07 m2 : 8|16@1+ (0.01,-100) [-100|555.35] "C"  ChargeCart,VCU_BeagleBone
 SG_ TempChannel08 m2 : 24|16@1+ (0.01,-100) [-100|555.35] "C"  ChargeCart,VCU_BeagleBone
 SG_ TempChannel09 m2 : 40|16@1+ (0.01,-100) [-100|555.35] "C"  ChargeCart,VCU_BeagleBone
 SG_ TempChannel10 m3 : 8|16@1+ (0.01,-100) [-100|555.35] "C"  ChargeCart,VCU_BeagleBone
 SG_ TempChannel11 m3 : 24|16@1+ (0.01,-100) [-100|555.35] "C"  ChargeCart,VCU_BeagleBone
 SG_ TempChannel12 m3 : 40|16@1+ (0.01,-100) [-100|555.35] "C"  ChargeCart,VCU_BeagleBone
 SG_ TempChannel13 m4 : 8|16@1+ (0.01,-100) [-100|555.35] "C"  ChargeCart,VCU_BeagleBone
 SG_ TempChannel14 m4 : 24|16@1+ (0.01,-100) [-100|555.35] "C"  ChargeCart,VCU_BeagleBone
 SG_ TempChannel15 m4 : 40|16@1+ (0.01,-100) [-100|555.35] "C"  ChargeCart,VCU_BeagleBone
 SG_ TempChannel16 m5 : 8|16@1+ (0.01,-100) [-100|555.35] "C"  ChargeCart,VCU_BeagleBone
 SG_ TempChannel17 m5 : 24|16@1+ (0.01,-100) [-100|555.35] "C"  ChargeCart,VCU_BeagleBone
 SG_ TempChannel18 m5 : 40|16@1+ (0.01,-100) [-100|555.35] "C"  ChargeCart,VCU_BeagleBone
 SG_ TempChannel19 m6 : 8|16@1+ (0.01,-100) [-100|555.35] "C"  ChargeCart,VCU_BeagleBone
 SG_ TempChannel20 m6 : 24|16@1+ (0.01,-100) [-100|555.35] "C"  ChargeCart,VCU_BeagleBone
 SG_ TempChannel21 m6 : 40|16@1+ (0.01,-100) [-100|555.35] "C"  ChargeCart,VCU_BeagleBone
 SG_ TempChannel22 m7 : 8|16@1+ (0.01,-100) [-100|555.35] "C"  ChargeCart,VCU_BeagleBone
 SG_ TempChannel23 m7 : 24|16@1+ (0.01,-100) [-100|555.35] "C"  ChargeCart,VCU_BeagleBone
 SG_ TempChannel24 m7 : 40|16@1+ (0.01,-100) [-100|555.35] "C"  ChargeCart,VCU_BeagleBone
 SG_ TempChannel25 m8 : 8|16@1+ (0.01,-100) [-100|555.35] "C"  ChargeCart,VCU_BeagleBone
 SG_ TempChannel26 m8 : 24|16@1+ (0.01,-100) [-100|555.35] "C"  ChargeCart,VCU_BeagleBone
 SG_ TempChannel27 m8 : 40|16@1+ (0.01,-100) [-100|555.35] "C"  ChargeCart,VCU_BeagleBone
 SG_ TempChannel28 m9 : 8|16@1+ (0.01,-100) [-100|555.35] "C"  ChargeCart,VCU_BeagleBone
 SG_ TempChannel29 m9 : 24|16@1+ (0.01,-100) [-100|555.35] "C"  ChargeCart,VCU_BeagleBone
 SG_ TempChannel30 m9 : 40|16@1+ (0.01,-100) [-100|555.35] "C"  ChargeCart,VCU_BeagleBone
 SG_ TempChannel31 m10 : 8|16@1+ (0.01,-100) [-100|555.35] "C"  ChargeCart,VCU_BeagleBone
 SG_ TempChannel32 m10 : 24|16@1+ (0.01,-100) [-100|555.35] "C"  ChargeCart,VCU_BeagleBone
 SG_ TempChannel33 m10 : 40|16@1+ (0.01,-100) [-100|555.35] "C"  ChargeCart,VCU_BeagleBone
 SG_ TempChannel34 m11 : 8|16@1+ (0.01,-100) [-100|555.35] "C"  ChargeCart,VCU_BeagleBone
 SG_ TempChannel35 m11 : 24|16@1+ (0.01,-100) [-100|555.35] "C"  ChargeCart,VCU_BeagleBone
 SG_ TempChannel36 m11 : 40|16@1+ (0.01,-100) [-100|555.35] "C"  ChargeCart,VCU_BeagleBone
 SG_ TempChannel37 m12 : 8|16@1+ (0.01,-100) [-100|555.35] "C"  ChargeCart,VCU_BeagleBone
 SG_ TempChannel38 m12 : 24|16@1+ (0.01,-100) [-100|555.35] "C"  ChargeCart,VCU_BeagleBone
 SG_ TempChannel39 m12 : 40|16@1+ (0.01,-100) [-100|555.35] "C"  ChargeCart,VCU_BeagleBone
 SG_ TempChannel40 m13 : 8|16@1+ (0.01,-100) [-100|555.35] "C"  ChargeCart,VCU_BeagleBone
 SG_ TempChannel41 m13 : 24|16@1+ (0.01,-100) [-100|555.35] "C"  ChargeCart,VCU_BeagleBone
 SG_ TempChannel42 m13 : 40|16@1+ (0.01,-100) [-100|555.35] "C"  ChargeCart,VCU_BeagleBone
 SG_ TempChannel43 m14 : 8|16@1+ (0.01,-100) [-100|555.35] "C"  ChargeCart,VCU_BeagleBone
 SG_ TempChannel44 m14 : 24|16@1+ (0.01,-100) [-100|555.35] "C"  ChargeCart,VCU_BeagleBone
 SG_ TempChannel45 m14 : 40|16@1+ (0.01,-100) [-100|555.35] "C"  ChargeCart,VCU_BeagleBone
 SG_ TempChannel46 m15 : 8|16@1+ (0.01,-100) [-100|555.35] "C"  ChargeCart,VCU_BeagleBone
 SG_ TempChannel47 m15 : 24|16@1+ (0.01,-100) [-100|555.35] "C"  ChargeCart,VCU_BeagleBone
 SG_ TempChannel48 m15 : 40|16@1+ (0.01,-100) [-100|555.35] "C"  ChargeCart,VCU_BeagleBone
 SG_ TempChannel49 m16 : 8|16@1+ (0.01,-100) [-100|555.35] "C"  ChargeCart,VCU_BeagleBone
 SG_ TempChannel50 m16 : 24|16@1+ (0.01,-100) [-100|555.35] "C"  ChargeCart,VCU_BeagleBone
 SG_ TempChannel51 m16 : 40|16@1+ (0.01,-100) [-100|555.35] "C"  ChargeCart,VCU_BeagleBone
 SG_ TempChannel52 m17 : 8|16@1+ (0.01,-100) [-100|555.35] "C"  ChargeCart,VCU_BeagleBone
 SG_ TempChannel53 m17 : 24|16@1+ (0.01,-100) [-100|555.35] "C"  ChargeCart,VCU_BeagleBone
 SG_ TempChannel54 m17 : 40|16@1+ (0.01,-100) [-100|555.35] "C"  ChargeCart,VCU_BeagleBone
 SG_ TempChannel55 m18 : 8|16@1+ (0.01,-100) [-100|555.35] "C"  ChargeCart,VCU_BeagleBone
 SG_ TempChannel56 m18 : 24|16@1+ (0.01,-100) [-100|555.35] "C"  ChargeCart,VCU_BeagleBone
 SG_ TempChannel57 m18 : 40|16@1+ (0.01,-100) [-100|555.35] "C"  ChargeCart,VCU_BeagleBone
 SG_ TempChannel58 m19 : 8|16@1+ (0.01,-100) [-100|555.35] "C"  ChargeCart,VCU_BeagleBone
 SG_ TempChannel59 m19 : 24|16@1+ (0.01,-100) [-100|555.35] "C"  ChargeCart,VCU_BeagleBone
 SG_ TempChannel60 m19 : 40|16@1+ (0.01,-100) [-100|555.35] "C"  ChargeCart,VCU_BeagleBone
 SG_ TempChannel61 m20 : 8|16@1+ (0.01,-100) [-100|555.35] "C"  VCU_BeagleBone,ChargeCart
 SG_ TempChannel62 m20 : 24|16@1+ (0.01,-100) [-100|555.35] "C"  VCU_BeagleBone,ChargeCart
 SG_ TempChannel63 m20 : 40|16@1+ (0.01,-100) [-100|555.35] "C"  VCU_BeagleBone,ChargeCart
 SG_ TempChannel64 m21 : 8|16@1+ (0.01,-100) [-100|555.35] "C"  VCU_BeagleBone,ChargeCart
 SG_ TempChannel65 m21 : 24|16@1+ (0.01,-100) [-100|555.35] "C"  VCU_BeagleBone,ChargeCart
 SG_ TempChannel66 m21 : 40|16@1+ (0.01,-100) [-100|555.35] "C"  VCU_BeagleBone,ChargeCart
 SG_ TempChannel67 m22 : 8|16@1+ (0.01,-100) [-100|555.35] "C"  VCU_BeagleBone,ChargeCart
 SG_ TempChannel68 m22 : 24|16@1+ (0.01,-100) [-100|555.35] "C"  VCU_BeagleBone,ChargeCart
 SG_ TempChannel69 m22 : 40|16@1+ (0.01,-100) [-100|555.35] "C"  VCU_BeagleBone,ChargeCart
 SG_ TempChannel70 m23 : 8|16@1+ (0.01,-100) [-100|555.35] "C"  VCU_BeagleBone,ChargeCart
 SG_ TempChannel71 m23 : 24|16@1+ (0.01,-100) [-100|555.35] "C"  VCU_BeagleBone,ChargeCart
 SG_ TempChannel72 m23 : 40|16@1+ (0.01,-100) [-100|555.35] "C"  VCU_BeagleBone,ChargeCart
 SG_ TempChannel73 m24 : 8|16@1+ (0.01,-100) [-100|555.35] "C"  VCU_BeagleBone,ChargeCart
 SG_ TempChannel74 m24 : 24|16@1+ (0.01,-100) [-100|555.35] "C"  VCU_BeagleBone,ChargeCart
 SG_ TempChannel75 m24 : 40|16@1+ (0.01,-100) [-100|555.35] "C"  VCU_BeagleBone,ChargeCart
 SG_ TempChannel76 m25 : 8|16@1+ (0.01,-100) [-100|555.35] "C"  VCU_BeagleBone,ChargeCart
 SG_ TempChannel77 m25 : 24|16@1+ (0.01,-100) [-100|555.35] "C"  VCU_BeagleBone,ChargeCart
 SG_ TempChannel78 m25 : 40|16@1+ (0.01,-100) [-100|555.35] "C"  VCU_BeagleBone,ChargeCart
 SG_ TempChannel79 m26 : 8|16@1+ (0.01,-100) [-100|555.35] "C"  VCU_BeagleBone,ChargeCart
 SG_ TempChannel80 m26 : 24|16@1+ (0.01,-100) [-100|555.35] "C"  VCU_BeagleBone,ChargeCart
 SG_ TempChannel81 m26 : 40|16@1+ (0.01,-100) [-100|555.35] "C"  VCU_BeagleBone,ChargeCart
 SG_ TempChannel82 m27 : 8|16@1+ (0.01,-100) [-100|555.35] "C"  VCU_BeagleBone,ChargeCart
 SG_ TempChannel83 m27 : 24|16@1+ (0.01,-100) [-100|555.35] "C"  VCU_BeagleBone,ChargeCart
 SG_ TempChannel84 m27 : 40|16@1+ (0.01,-100) [-100|555.35] "C"  VCU_BeagleBone,ChargeCart
 SG_ TempChannel85 m28 : 8|16@1+ (0.01,-100) [-100|555.35] "C"  VCU_BeagleBone,ChargeCart
 SG_ TempChannel86 m28 : 24|16@1+ (0.01,-100) [-100|555.35] "C"  VCU_BeagleBone,ChargeCart
 SG_ TempChannel87 m28 : 40|16@1+ (0.01,-100) [-100|555.35] "C"  VCU_BeagleBone,ChargeCart
 SG_ TempChannel88 m29 : 8|16@1+ (0.01,-100) [-100|555.35] "C"  VCU_BeagleBone,ChargeCart
 SG_ TempChannel89 m29 : 24|16@1+ (0.01,-100) [-100|555.35] "C"  VCU_BeagleBone,ChargeCart
 SG_ TempChannel90 m29 : 40|16@1+ (0.01,-100) [-100|555.35] "C"  VCU_BeagleBone,ChargeCart
 SG_ TempChannel91 m30 : 8|16@1+ (0.01,-100) [-100|555.35] "C"  VCU_BeagleBone,ChargeCart
 SG_ TempChannel92 m30 : 24|16@1+ (0.01,-100) [-100|555.35] "C"  VCU_BeagleBone,ChargeCart
 SG_ TempChannel93 m30 : 40|16@1+ (0.01,-100) [-100|555.35] "C"  VCU_BeagleBone,ChargeCart
 SG_ TempChannel94 m31 : 8|16@1+ (0.01,-100) [-100|555.35] "C"  VCU_BeagleBone,ChargeCart
 SG_ TempChannel95 m31 : 24|16@1+ (0.01,-100) [-100|555.35] "C"  VCU_BeagleBone,ChargeCart
 SG_ TempChannel96 m31 : 40|16@1+ (0.01,-100) [-100|555.35] "C"  VCU_BeagleBone,ChargeCart
 SG_ TempChannel97 m32 : 8|16@1+ (0.01,-100) [-100|555.35] "C"  VCU_BeagleBone,ChargeCart
 SG_ TempChannel98 m32 : 24|16@1+ (0.01,-100) [-100|555.35] "C"  VCU_BeagleBone,ChargeCart
 SG_ TempChannel99 m32 : 40|16@1+ (0.01,-100) [-100|555.35] "C"  VCU_BeagleBone,ChargeCart
 SG_ TempChannel100 m33 : 8|16@1+ (0.01,-100) [-100|555.35] "C"  VCU_BeagleBone,ChargeCart
 SG_ TempChannel101 m33 : 24|16@1+ (0.01,-100) [-100|555.35] "C"  VCU_BeagleBone,ChargeCart
 SG_ TempChannel102 m33 : 40|16@1+ (0.01,-100) [-100|555.35] "C"  VCU_BeagleBone,ChargeCart
 SG_ TempChannel103 m34 : 8|16@1+ (0.01,-100) [-100|555.35] "C"  VCU_BeagleBone,ChargeCart
 SG_ TempChannel104 m34 : 24|16@1+ (0.01,-100) [-100|555.35] "C"  VCU_BeagleBone,ChargeCart
 SG_ TempChannel105 m34 : 40|16@1+ (0.01,-100) [-100|555.35] "C"  VCU_BeagleBone,ChargeCart
 SG_ TempChannel106 m35 : 8|16@1+ (0.01,-100) [-100|555.35] "C"  VCU_BeagleBone,ChargeCart
 SG_ TempChannel107 m35 : 24|16@1+ (0.01,-100) [-100|555.35] "C"  VCU_BeagleBone,ChargeCart
 SG_ TempChannel108 m35 : 40|16@1+ (0.01,-100) [-100|555.35] "C"  VCU_BeagleBone,ChargeCart
 SG_ TempChannel109 m36 : 8|16@1+ (0.01,-100) [-100|555.35] "C"  VCU_BeagleBone,ChargeCart
 SG_ TempChannel110 m36 : 24|16@1+ (0.01,-100) [-100|555.35] "C"  VCU_BeagleBone,ChargeCart
 SG_ TempChannel111 m36 : 40|16@1+ (0.01,-100) [-100|555.35] "C"  VCU_BeagleBone,ChargeCart
 SG_ TempChannel112 m37 : 8|16@1+ (0.01,-100) [-100|555.35] "C"  VCU_BeagleBone,ChargeCart
 SG_ TempChannel113 m37 : 24|16@1+ (0.01,-100) [-100|555.35] "C"  VCU_BeagleBone,ChargeCart
 SG_ TempChannel114 m37 : 40|16@1+ (0.01,-100) [-100|555.35] "C"  VCU_BeagleBone,ChargeCart
 SG_ TempChannel115 m38 : 8|16@1+ (0.01,-100) [-100|555.35] "C"  VCU_BeagleBone,ChargeCart
 SG_ TempChannel116 m38 : 24|16@1+ (0.01,-100) [-100|555.35] "C"  VCU_BeagleBone,ChargeCart
 SG_ TempChannel117 m38 : 40|16@1+ (0.01,-100) [-100|555.35] "C"  VCU_BeagleBone,ChargeCart
 SG_ TempChannel118 m39 : 8|16@1+ (0.01,-100) [-100|555.35] "C"  VCU_BeagleBone,ChargeCart
 SG_ TempChannel119 m39 : 24|16@1+ (0.01,-100) [-100|555.35] "C"  VCU_BeagleBone,ChargeCart
 SG_ TempChannel120 m39 : 40|16@1+ (0.01,-100) [-100|555.35] "C"  VCU_BeagleBone,ChargeCart
 SG_ TempChannel121 m40 : 8|16@1+ (0.01,-100) [-100|555.35] "C"  VCU_BeagleBone,ChargeCart
 SG_ TempChannel122 m40 : 24|16@1+ (0.01,-100) [-100|555.35] "C"  VCU_BeagleBone,ChargeCart
 SG_ TempChannel123 m40 : 40|16@1+ (0.01,-100) [-100|555.35] "C"  VCU_BeagleBone,ChargeCart
 SG_ TempChannel124 m41 : 8|16@1+ (0.01,-100) [-100|555.35] "C"  VCU_BeagleBone,ChargeCart
 SG_ TempChannel125 m41 : 24|16@1+ (0.01,-100) [-100|555.35] "C"  VCU_BeagleBone,ChargeCart
 SG_ TempChannel126 m41 : 40|16@1+ (0.01,-100) [-100|555.35] "C"  VCU_BeagleBone,ChargeCart
 SG_ TempChannel127 m42 : 8|16@1+ (0.01,-100) [-100|555.35] "C"  VCU_BeagleBone,ChargeCart
 SG_ TempChannel128 m42 : 24|16@1+ (0.01,-100) [-100|555.35] "C"  VCU_BeagleBone,ChargeCart
 SG_ TempChannel129 m42 : 40|16@1+ (0.01,-100) [-100|555.35] "C"  VCU_BeagleBone,ChargeCart
 SG_ TempChannel130 m43 : 8|16@1+ (0.01,-100) [-100|555.35] "C"  VCU_BeagleBone,ChargeCart
 SG_ TempChannel131 m43 : 24|16@1+ (0.01,-100) [-100|555.35] "C"  VCU_BeagleBone,ChargeCart
 SG_ TempChannel132 m43 : 40|16@1+ (0.01,-100) [-100|555.35] "C"  VCU_BeagleBone,ChargeCart
 SG_ TempChannel133 m44 : 8|16@1+ (0.01,-100) [-100|555.35] "C"  VCU_BeagleBone,ChargeCart
 SG_ TempChannel134 m44 : 24|16@1+ (0.01,-100) [-100|555.35] "C"  VCU_BeagleBone,ChargeCart
 SG_ TempChannel135 m44 : 40|16@1+ (0.01,-100) [-100|555.35] "C"  VCU_BeagleBone,ChargeCart
 SG_ TempChannel136 m45 : 8|16@1+ (0.01,-100) [-100|555.35] "C"  VCU_BeagleBone,ChargeCart
 SG_ TempChannel137 m45 : 24|16@1+ (0.01,-100) [-100|555.35] "C"  VCU_BeagleBone,ChargeCart
 SG_ TempChannel138 m45 : 40|16@1+ (0.01,-100) [-100|555.35] "C"  VCU_BeagleBone,ChargeCart
 SG_ TempChannel139 m46 : 8|16@1+ (0.01,-100) [-100|555.35] "C"  VCU_BeagleBone,ChargeCart
 SG_ TempChannel140 m46 : 24|16@1+ (0.01,-100) [-100|555.35] "C"  VCU_BeagleBone,ChargeCart
 SG_ TempChannel141 m46 : 40|16@1+ (0.01,-100) [-100|555.35] "C"  VCU_BeagleBone,ChargeCart
 SG_ TempChannel142 m47 : 8|16@1+ (0.01,-100) [-100|555.35] "C"  VCU_BeagleBone,ChargeCart
 SG_ TempChannel143 m47 : 24|16@1+ (0.01,-100) [-100|555.35] "C"  VCU_BeagleBone,ChargeCart
 SG_ TempChannel144 m47 : 40|16@1+ (0.01,-100) [-100|555.35] "C"  VCU_BeagleBone,ChargeCart
 SG_ TempChannel145 m48 : 8|16@1+ (0.01,-100) [-100|555.35] "C"  VCU_BeagleBone,ChargeCart
 SG_ TempChannel146 m48 : 24|16@1+ (0.01,-100) [-100|555.35] "C"  VCU_BeagleBone,ChargeCart
 SG_ TempChannel147 m48 : 40|16@1+ (0.01,-100) [-100|555.35] "C"  VCU_BeagleBone,ChargeCart
 SG_ TempChannel148 m49 : 8|16@1+ (0.01,-100) [-100|555.35] "C"  VCU_BeagleBone,ChargeCart
 SG_ TempChannel149 m49 : 24|16@1+ (0.01,-100) [-100|555.35] "C"  VCU_BeagleBone,ChargeCart
 SG_ TempChannel150 m49 : 40|16@1+ (0.01,-100) [-100|555.35] "C"  VCU_BeagleBone,ChargeCart
 SG_ TempChannel151 m50 : 8|16@1+ (0.01,-100) [-100|555.35] "C"  VCU_BeagleBone,ChargeCart
 SG_ TempChannel152 m50 : 24|16@1+ (0.01,-100) [-100|555.35] "C"  VCU_BeagleBone,ChargeCart
 SG_ TempChannel153 m50 : 40|16@1+ (0.01,-100) [-100|555.35] "C"  VCU_BeagleBone,ChargeCart
 SG_ TempChannel154 m51 : 8|16@1+ (0.01,-100) [-100|555.35] "C"  VCU_BeagleBone,ChargeCart
 SG_ TempChannel155 m51 : 24|16@1+ (0.01,-100) [-100|555.35] "C"  VCU_BeagleBone,ChargeCart
 SG_ TempChannel156 m51 : 40|16@1+ (0.01,-100) [-100|555.35] "C"  VCU_BeagleBone,ChargeCart
 SG_ TempChannel157 m52 : 8|16@1+ (0.01,-100) [-100|555.35] "C"  VCU_BeagleBone,ChargeCart
 SG_ TempChannel158 m52 : 24|16@1+ (0.01,-100) [-100|555.35] "C"  VCU_BeagleBone,ChargeCart
 SG_ TempChannel159 m52 : 40|16@1+ (0.01,-100) [-100|555.35] "C"  VCU_BeagleBone,ChargeCart
 SG_ TempChannel160 m53 : 8|16@1+ (0.01,-100) [-100|555.35] "C"  VCU_BeagleBone,ChargeCart
 SG_ TempChannel161 m53 : 24|16@1+ (0.01,-100) [-100|555.35] "C"  VCU_BeagleBone,ChargeCart
 SG_ TempChannel162 m53 : 40|16@1+ (0.01,-100) [-100|555.35] "C"  VCU_BeagleBone,ChargeCart
 SG_ TempChannel163 m54 : 8|16@1+ (0.01,-100) [-100|555.35] "C"  VCU_BeagleBone,ChargeCart
 SG_ TempChannel164 m54 : 24|16@1+ (0.01,-100) [-100|555.35] "C"  VCU_BeagleBone,ChargeCart
 SG_ TempChannel165 m54 : 40|16@1+ (0.01,-100) [-100|555.35] "C"  VCU_BeagleBone,ChargeCart
 SG_ TempChannel166 m55 : 8|16@1+ (0.01,-100) [-100|555.35] "C"  VCU_BeagleBone,ChargeCart
 SG_ TempChannel167 m55 : 24|16@1+ (0.01,-100) [-100|555.35] "C"  VCU_BeagleBone,ChargeCart
 SG_ TempChannel168 m55 : 40|16@1+ (0.01,-100) [-100|555.35] "C"  VCU_BeagleBone,ChargeCart
 SG_ TempChannel169 m56 : 8|16@1+ (0.01,-100) [-100|555.35] "C"  VCU_BeagleBone,ChargeCart
 SG_ TempChannel170 m56 : 24|16@1+ (0.01,-100) [-100|555.35] "C"  VCU_BeagleBone,ChargeCart
 SG_ TempChannel171 m56 : 40|16@1+ (0.01,-100) [-100|555.35] "C"  VCU_BeagleBone,ChargeCart
 SG_ TempChannel172 m57 : 8|16@1+ (0.01,-100) [-100|555.35] "C"  VCU_BeagleBone,ChargeCart
 SG_ TempChannel173 m57 : 24|16@1+ (0.01,-100) [-100|555.35] "C"  VCU_BeagleBone,ChargeCart
 SG_ TempChannel174 m57 : 40|16@1+ (0.01,-100) [-100|555.35] "C"  VCU_BeagleBone,ChargeCart
 SG_ TempChannel175 m58 : 8|16@1+ (0.01,-100) [-100|555.35] "C"  VCU_BeagleBone,ChargeCart
 SG_ TempChannel176 m58 : 24|16@1+ (0.01,-100) [-100|555.35] "C"  VCU_BeagleBone,ChargeCart
 SG_ TempChannel177 m58 : 40|16@1+ (0.01,-100) [-100|555.35] "C"  VCU_BeagleBone,ChargeCart
 SG_ TempChannel178 m59 : 8|16@1+ (0.01,-100) [-100|555.35] "C"  VCU_BeagleBone,ChargeCart
 SG_ TempChannel179 m59 : 24|16@1+ (0.01,-100) [-100|555.35] "C"  VCU_BeagleBone,ChargeCart
 SG_ TempChannel180 m59 : 40|16@1+ (0.01,-100) [-100|555.35] "C"  VCU_BeagleBone,ChargeCart
 SG_ TempChannel181 m60 : 8|16@1+ (0.01,-100) [-100|555.35] "C"  VCU_BeagleBone,ChargeCart
 SG_ TempChannel182 m60 : 24|16@1+ (0.01,-100) [-100|555.35] "C"  VCU_BeagleBone,ChargeCart
 SG_ TempChannel183 m60 : 40|16@1+ (0.01,-100) [-100|555.35] "C"  VCU_BeagleBone,ChargeCart
 SG_ TempChannel184 m61 : 8|16@1+ (0.01,-100) [-100|555.35] "C"  VCU_BeagleBone,ChargeCart
 SG_ TempChannel185 m61 : 24|16@1+ (0.01,-100) [-100|555.35] "C"  VCU_BeagleBone,ChargeCart
 SG_ TempChannel186 m61 : 40|16@1+ (0.01,-100) [-100|555.35] "C"  VCU_BeagleBone,ChargeCart
 SG_ TempChannel187 m62 : 8|16@1+ (0.01,-100) [-100|555.35] "C"  VCU_BeagleBone,ChargeCart
 SG_ TempChannel188 m62 : 24|16@1+ (0.01,-100) [-100|555.35] "C"  VCU_BeagleBone,ChargeCart
 SG_ TempChannel189 m62 : 40|16@1+ (0.01,-100) [-100|555.35] "C"  VCU_BeagleBone,ChargeCart

BO_ 2281703170 VCU_Status: 8 VCU_F7
 SG_ SpeedVehicleVCU : 0|18@1- (0.00068664812716723,60) [-30.0003433240632|149.999656675936] "rad/s"  VCU_BeagleBone,DCU

BO_ 2550137363 TempCoolantRight: 8 WSBRR
 SG_ TempOutletRadMotorRight : 10|10@1- (0.25,90) [-38|217.75] "C"  VCU_BeagleBone,VCU_F7
 SG_ TempInletRadMotorRight : 0|10@1- (0.25,90) [-38|217.75] "C"  VCU_BeagleBone,VCU_F7

BO_ 2550137362 TempCoolantLeft: 8 WSBRL
 SG_ TempOutletRadMotorLeft : 10|10@1- (0.25,90) [-38|217.75] "C"  VCU_BeagleBone,VCU_F7
 SG_ TempInletRadMotorLeft : 0|10@1- (0.25,90) [-38|217.75] "C"  VCU_BeagleBone,VCU_F7

BO_ 2214662151 DCU_buttonEvents: 8 DCU
 SG_ ButtonEnduranceToggleEnabled : 4|1@1+ (1,0) [0|0] "bool"  VCU_BeagleBone,VCU_F7
 SG_ ButtonEnduranceLapEnabled : 3|1@1+ (1,0) [0|0] "bool"  VCU_BeagleBone,VCU_F7
 SG_ ButtonTCEnabled : 2|1@1+ (1,0) [0|0] "bool"  VCU_BeagleBone,VCU_F7
 SG_ ButtonHVEnabled : 1|1@1+ (1,0) [0|0] "bool"  BMU,VCU_BeagleBone,VCU_F7
 SG_ ButtonEMEnabled : 0|1@1+ (1,0) [0|0] "bool"  VCU_BeagleBone,VCU_F7

BO_ 2550141444 ChargeCart_VERSION: 8 ChargeCart
 SG_ ChargeCart_Version_DB : 0|8@1- (1,0) [0|0] ""  VCU_BeagleBone
 SG_ ChargeCart_Version_code : 8|56@1- (1,0) [0|0] ""  VCU_BeagleBone

BO_ 2550141441 BMU_VERSION: 8 BMU
 SG_ BMU_Version_DB : 0|8@1- (1,0) [0|0] ""  VCU_BeagleBone
 SG_ BMU_Version_code : 8|56@1- (1,0) [0|0] ""  VCU_BeagleBone

BO_ 2550136839 DCU_VERSION: 8 DCU
 SG_ DCU_Version_DB : 0|8@1- (1,0) [0|0] ""  VCU_BeagleBone
 SG_ DCU_Version_code : 8|56@1- (1,0) [0|0] ""  VCU_BeagleBone

BO_ 2550141443 PDU_VERSION: 8 PDU
 SG_ PDU_Version_DB : 0|8@1- (1,0) [0|0] ""  VCU_BeagleBone
 SG_ PDU_Version_code : 8|56@1- (1,0) [0|0] ""  VCU_BeagleBone

BO_ 2550141442 VCU_VERSION: 8 VCU_F7
 SG_ VCU_Version_DB : 0|8@1- (1,0) [0|0] ""  VCU_BeagleBone
 SG_ VCU_Version_code : 8|56@1- (1,0) [0|0] ""  VCU_BeagleBone

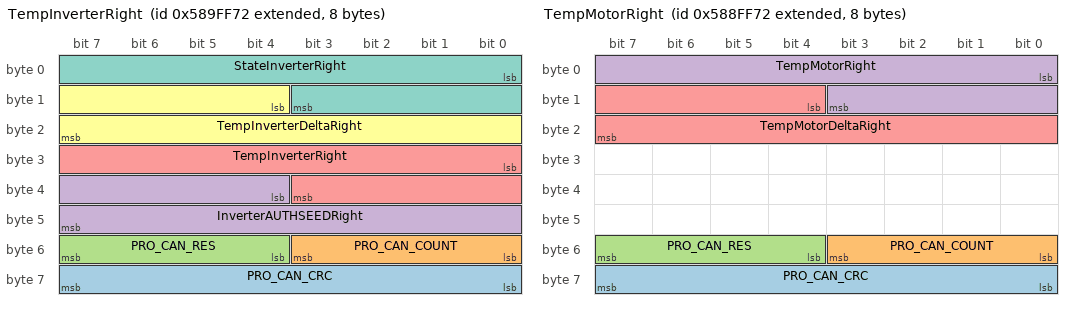
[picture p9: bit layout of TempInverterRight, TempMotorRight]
BO_ 2240413554 TempInverterRight: 8 MCRight
 SG_ PRO_CAN_CRC : 56|8@1+ (1,0) [0|255] "" Vector__XXX
 SG_ PRO_CAN_COUNT : 48|4@1+ (1,0) [0|15] "" Vector__XXX
 SG_ PRO_CAN_RES : 52|4@1+ (1,0) [0|15] "" Vector__XXX
 SG_ InverterAUTHSEEDRight : 36|12@1+ (1,0) [0|4095] "" Vector__XXX
 SG_ TempInverterRight : 24|12@1+ (1,-640) [-640|3455] "C"  VCU_BeagleBone,VCU_F7
 SG_ TempInverterDeltaRight : 12|12@1+ (1,-640) [-640|3455] "C"  VCU_BeagleBone,VCU_F7
 SG_ StateInverterRight : 0|12@1+ (1,0) [0|4095] ""  VCU_BeagleBone,VCU_F7

BO_ 2240348018 TempMotorRight: 8 MCRight
 SG_ PRO_CAN_CRC : 56|8@1+ (1,0) [0|255] "" Vector__XXX
 SG_ PRO_CAN_COUNT : 48|4@1+ (1,0) [0|15] "" Vector__XXX
 SG_ PRO_CAN_RES : 52|4@1+ (1,0) [0|15] "" Vector__XXX
 SG_ TempMotorRight : 0|12@1+ (1,-640) [-640|3455] "C"  VCU_BeagleBone,VCU_F7
 SG_ TempMotorDeltaRight : 12|12@1+ (1,-640) [-640|3455] "C"  VCU_BeagleBone,VCU_F7

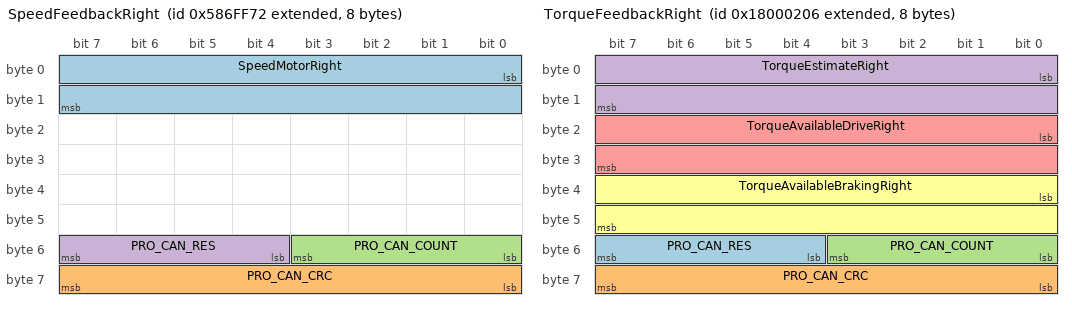
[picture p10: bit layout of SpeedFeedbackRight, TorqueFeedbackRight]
BO_ 2240216946 SpeedFeedbackRight: 8 MCRight
 SG_ SpeedMotorRight : 0|16@1+ (1,-0) [0|65535] "RPM"  VCU_BeagleBone,VCU_F7
 SG_ PRO_CAN_CRC : 56|8@1+ (1,0) [0|255] "" Vector__XXX
 SG_ PRO_CAN_COUNT : 48|4@1+ (1,0) [0|0] "" Vector__XXX
 SG_ PRO_CAN_RES : 52|4@1+ (1,0) [0|0] "" Vector__XXX

BO_ 2550137350 TorqueFeedbackRight: 8 MCRight
 SG_ PRO_CAN_RES : 52|4@1+ (1,0) [0|15] "" Vector__XXX
 SG_ PRO_CAN_CRC : 56|8@1+ (1,0) [0|255] "" Vector__XXX
 SG_ PRO_CAN_COUNT : 48|4@1+ (1,0) [0|15] "" Vector__XXX
 SG_ TorqueEstimateRight : 0|16@1+ (1,0) [0|0] ""  VCU_BeagleBone,VCU_F7
 SG_ TorqueAvailableDriveRight : 16|16@1+ (1,0) [0|0] ""  VCU_BeagleBone,VCU_F7
 SG_ TorqueAvailableBrakingRight : 32|16@1+ (1,0) [0|0] ""  VCU_BeagleBone,VCU_F7

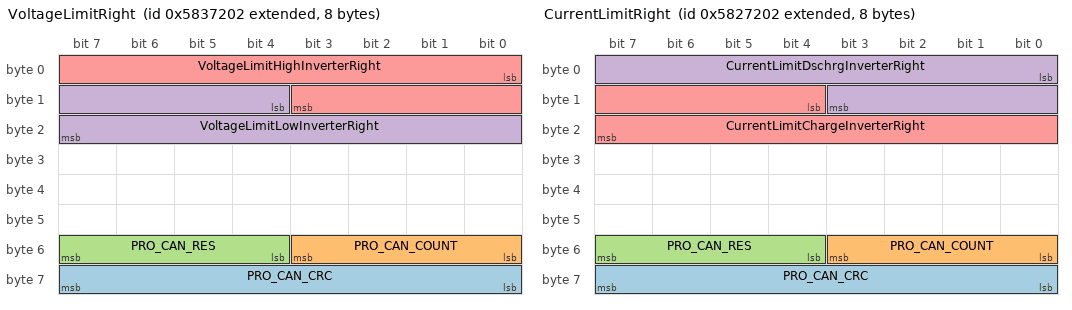
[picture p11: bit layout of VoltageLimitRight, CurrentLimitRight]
BO_ 2239984130 VoltageLimitRight: 8 VCU_F7
 SG_ PRO_CAN_CRC : 56|8@1+ (1,0) [0|255] "" Vector__XXX
 SG_ PRO_CAN_COUNT : 48|4@1+ (1,0) [0|15] "" Vector__XXX
 SG_ PRO_CAN_RES : 52|4@1+ (1,0) [0|15] "" Vector__XXX
 SG_ VoltageLimitLowInverterRight : 12|12@1+ (1,0) [0|4095] "V"  VCU_BeagleBone,MCRight
 SG_ VoltageLimitHighInverterRight : 0|12@1+ (1,0) [0|4095] "V"  VCU_BeagleBone,MCRight

BO_ 2239918594 CurrentLimitRight: 8 VCU_F7
 SG_ PRO_CAN_CRC : 56|8@1+ (1,0) [0|0] "" Vector__XXX
 SG_ PRO_CAN_COUNT : 48|4@1+ (1,0) [0|15] "" Vector__XXX
 SG_ PRO_CAN_RES : 52|4@1+ (1,0) [0|0] "" Vector__XXX
 SG_ CurrentLimitDschrgInverterRight : 0|12@1+ (1,0) [0|4095] "A"  VCU_BeagleBone,MCRight
 SG_ CurrentLimitChargeInverterRight : 12|12@1+ (1,0) [0|4095] "A"  VCU_BeagleBone,MCRight

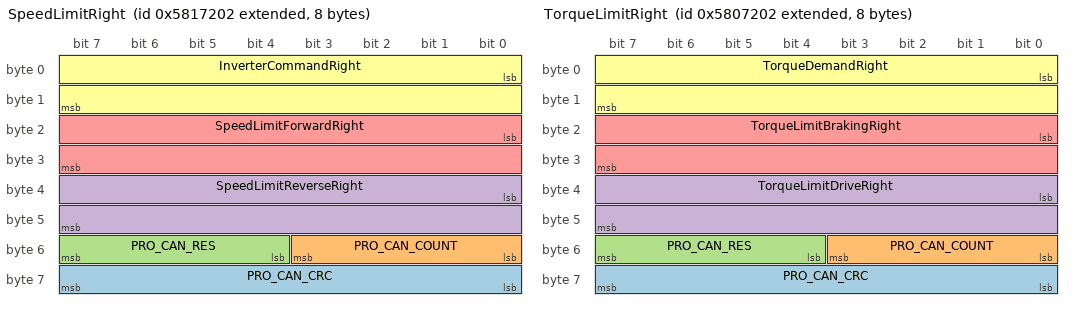
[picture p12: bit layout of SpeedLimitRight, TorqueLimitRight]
BO_ 2239853058 SpeedLimitRight: 8 VCU_F7
 SG_ PRO_CAN_CRC : 56|8@1+ (1,0) [0|0] "" Vector__XXX
 SG_ PRO_CAN_COUNT : 48|4@1+ (1,0) [0|0] "" Vector__XXX
 SG_ PRO_CAN_RES : 52|4@1+ (1,0) [0|15] "" Vector__XXX
 SG_ SpeedLimitReverseRight : 32|16@1+ (1,0) [0|65535] "RPM"  VCU_BeagleBone,MCRight
 SG_ SpeedLimitForwardRight : 16|16@1+ (1,0) [0|65535] "RPM"  VCU_BeagleBone,MCRight
 SG_ InverterCommandRight : 0|16@1+ (1,0) [0|65535] ""  VCU_BeagleBone,MCRight

BO_ 2239787522 TorqueLimitRight: 8 VCU_F7
 SG_ PRO_CAN_CRC : 56|8@1+ (1,0) [0|255] "" Vector__XXX
 SG_ PRO_CAN_COUNT : 48|4@1+ (1,0) [0|15] "" Vector__XXX
 SG_ PRO_CAN_RES : 52|4@1+ (1,0) [0|15] "" Vector__XXX
 SG_ TorqueLimitDriveRight : 32|16@1+ (0.0625,0) [0|4095.9375] "NM"  VCU_BeagleBone,MCRight
 SG_ TorqueLimitBrakingRight : 16|16@1+ (0.0625,0) [0|4095.9375] "NM"  VCU_BeagleBone,MCRight
 SG_ TorqueDemandRight : 0|16@1+ (0.0625,-2048) [-2048|2047.9375] "NM"  VCU_BeagleBone,MCRight

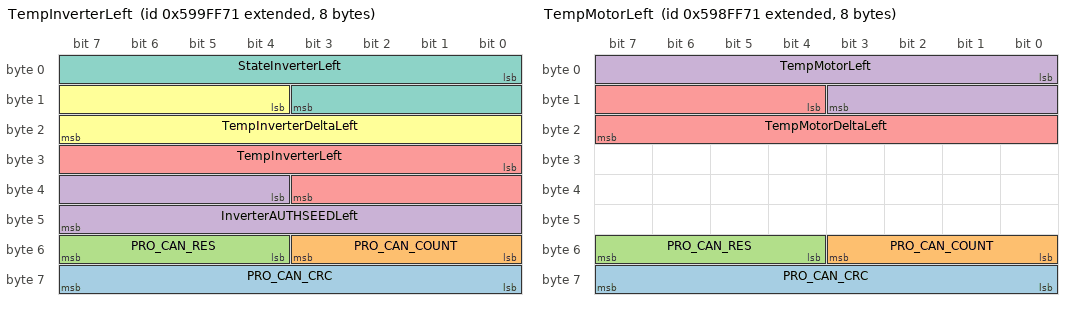
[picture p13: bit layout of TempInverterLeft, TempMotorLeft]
BO_ 2241462129 TempInverterLeft: 8 MCLeft
 SG_ PRO_CAN_CRC : 56|8@1+ (1,0) [0|255] "" Vector__XXX
 SG_ PRO_CAN_COUNT : 48|4@1+ (1,0) [0|15] "" Vector__XXX
 SG_ PRO_CAN_RES : 52|4@1+ (1,0) [0|15] "" Vector__XXX
 SG_ InverterAUTHSEEDLeft : 36|12@1+ (1,0) [0|4095] "" Vector__XXX
 SG_ TempInverterLeft : 24|12@1+ (1,-640) [-640|3455] "C"  VCU_BeagleBone,VCU_F7
 SG_ TempInverterDeltaLeft : 12|12@1+ (1,-640) [-640|3455] "C"  VCU_BeagleBone,VCU_F7
 SG_ StateInverterLeft : 0|12@1+ (1,0) [0|4095] ""  VCU_BeagleBone,VCU_F7

BO_ 2241396593 TempMotorLeft: 8 MCLeft
 SG_ PRO_CAN_CRC : 56|8@1+ (1,0) [0|255] "" Vector__XXX
 SG_ PRO_CAN_COUNT : 48|4@1+ (1,0) [0|15] "" Vector__XXX
 SG_ PRO_CAN_RES : 52|4@1+ (1,0) [0|15] "" Vector__XXX
 SG_ TempMotorLeft : 0|12@1+ (1,-640) [-640|3455] "C"  VCU_BeagleBone,VCU_F7
 SG_ TempMotorDeltaLeft : 12|12@1+ (1,-640) [-640|3455] "C"  VCU_BeagleBone,VCU_F7

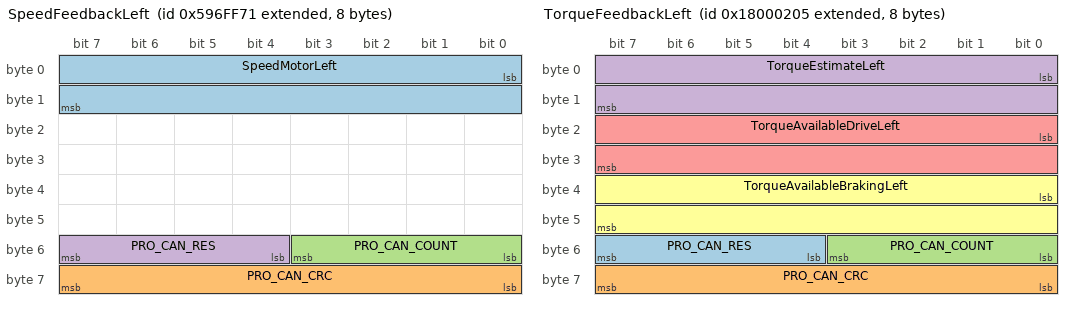
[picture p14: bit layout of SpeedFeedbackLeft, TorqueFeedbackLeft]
BO_ 2241265521 SpeedFeedbackLeft: 8 MCLeft
 SG_ SpeedMotorLeft : 0|16@1+ (1,0) [0|65535] "RPM"  VCU_BeagleBone,VCU_F7
 SG_ PRO_CAN_CRC : 56|8@1+ (1,0) [0|0] "" Vector__XXX
 SG_ PRO_CAN_COUNT : 48|4@1+ (1,0) [0|0] "" Vector__XXX
 SG_ PRO_CAN_RES : 52|4@1+ (1,0) [0|0] "" Vector__XXX

BO_ 2550137349 TorqueFeedbackLeft: 8 MCLeft
 SG_ PRO_CAN_RES : 52|4@1+ (1,0) [0|15] "" Vector__XXX
 SG_ PRO_CAN_CRC : 56|8@1+ (1,0) [0|255] "" Vector__XXX
 SG_ PRO_CAN_COUNT : 48|4@1+ (1,0) [0|15] "" Vector__XXX
 SG_ TorqueEstimateLeft : 0|16@1+ (1,0) [0|0] ""  VCU_BeagleBone,VCU_F7
 SG_ TorqueAvailableDriveLeft : 16|16@1+ (1,0) [0|0] ""  VCU_BeagleBone,VCU_F7
 SG_ TorqueAvailableBrakingLeft : 32|16@1+ (1,0) [0|0] ""  VCU_BeagleBone,VCU_F7

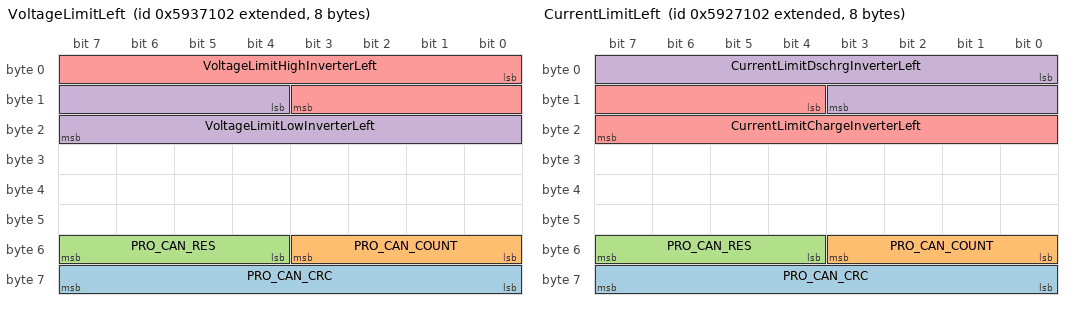
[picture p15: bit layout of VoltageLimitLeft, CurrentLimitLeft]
BO_ 2241032450 VoltageLimitLeft: 8 VCU_F7
 SG_ PRO_CAN_CRC : 56|8@1+ (1,0) [0|255] "" Vector__XXX
 SG_ PRO_CAN_COUNT : 48|4@1+ (1,0) [0|15] "" Vector__XXX
 SG_ PRO_CAN_RES : 52|4@1+ (1,0) [0|15] "" Vector__XXX
 SG_ VoltageLimitLowInverterLeft : 12|12@1+ (1,0) [0|4095] "V"  VCU_BeagleBone,MCLeft
 SG_ VoltageLimitHighInverterLeft : 0|12@1+ (1,0) [0|4095] "V"  VCU_BeagleBone,MCLeft

BO_ 2240966914 CurrentLimitLeft: 8 VCU_F7
 SG_ PRO_CAN_CRC : 56|8@1+ (1,0) [0|0] "" Vector__XXX
 SG_ PRO_CAN_COUNT : 48|4@1+ (1,0) [0|0] "" Vector__XXX
 SG_ PRO_CAN_RES : 52|4@1+ (1,0) [0|0] "" Vector__XXX
 SG_ CurrentLimitDschrgInverterLeft : 0|12@1+ (1,0) [0|4095] "A"  VCU_BeagleBone,MCLeft
 SG_ CurrentLimitChargeInverterLeft : 12|12@1+ (1,0) [0|4095] "A"  VCU_BeagleBone,MCLeft

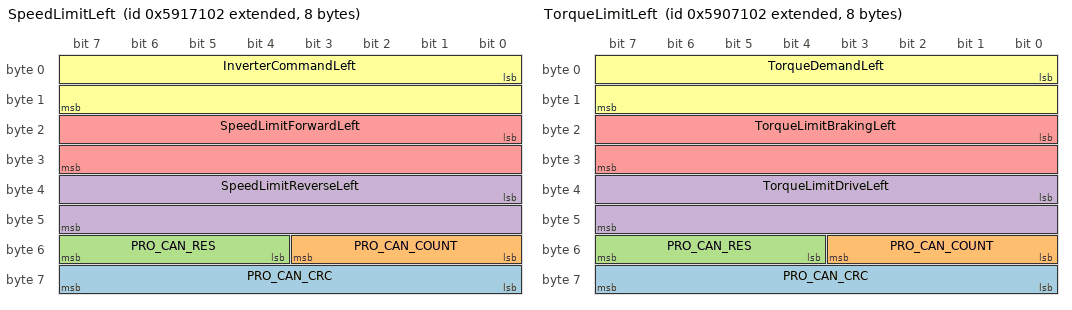
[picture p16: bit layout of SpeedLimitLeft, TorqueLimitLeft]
BO_ 2240901378 SpeedLimitLeft: 8 VCU_F7
 SG_ PRO_CAN_CRC : 56|8@1+ (1,0) [0|0] "" Vector__XXX
 SG_ PRO_CAN_COUNT : 48|4@1+ (1,0) [0|0] "" Vector__XXX
 SG_ PRO_CAN_RES : 52|4@1+ (1,0) [0|0] "" Vector__XXX
 SG_ SpeedLimitReverseLeft : 32|16@1+ (1,0) [0|65535] "RPM"  VCU_BeagleBone,MCLeft
 SG_ SpeedLimitForwardLeft : 16|16@1+ (1,0) [0|65535] "RPM"  VCU_BeagleBone,MCLeft
 SG_ InverterCommandLeft : 0|16@1+ (1,0) [0|65535] ""  VCU_BeagleBone,MCLeft

BO_ 2240835842 TorqueLimitLeft: 8 VCU_F7
 SG_ PRO_CAN_CRC : 56|8@1+ (1,0) [0|255] "" Vector__XXX
 SG_ PRO_CAN_COUNT : 48|4@1+ (1,0) [0|15] "" Vector__XXX
 SG_ PRO_CAN_RES : 52|4@1+ (1,0) [0|15] "" Vector__XXX
 SG_ TorqueLimitDriveLeft : 32|16@1+ (0.0625,0) [0|4095.9375] "NM"  VCU_BeagleBone,MCLeft
 SG_ TorqueLimitBrakingLeft : 16|16@1+ (0.0625,0) [0|4095.9375] "NM"  VCU_BeagleBone,MCLeft
 SG_ TorqueDemandLeft : 0|16@1+ (0.0625,-2048) [-2048|2047.9375] "NM"  VCU_BeagleBone,MCLeft

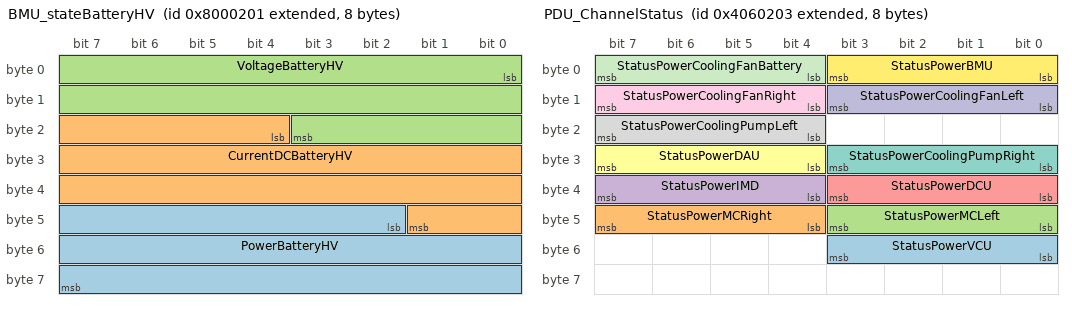
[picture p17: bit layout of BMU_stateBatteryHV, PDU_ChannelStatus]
BO_ 2281701889 BMU_stateBatteryHV: 8 BMU
 SG_ PowerBatteryHV : 42|22@1- (0.01,0) [0|0] "W"  VCU_BeagleBone,VCU_F7
 SG_ CurrentDCBatteryHV : 20|22@1- (0.001,0) [-2097.152|2097.151] "Amps"  VCU_BeagleBone,VCU_F7
 SG_ VoltageBatteryHV : 0|20@1+ (1,0) [0|1048575] "mV"  VCU_BeagleBone,VCU_F7

BO_ 2214986243 PDU_ChannelStatus: 8 PDU
 SG_ StatusPowerVCU : 48|4@1- (1,0) [0|0] ""  VCU_BeagleBone
 SG_ StatusPowerMCRight : 44|4@1- (1,0) [0|0] ""  VCU_F7,VCU_BeagleBone
 SG_ StatusPowerMCLeft : 40|4@1- (1,0) [0|0] ""  VCU_F7,VCU_BeagleBone
 SG_ StatusPowerIMD : 36|4@1- (1,0) [0|0] ""  VCU_BeagleBone
 SG_ StatusPowerDCU : 32|4@1- (1,0) [0|0] ""  VCU_BeagleBone
 SG_ StatusPowerDAU : 28|4@1- (1,0) [0|0] ""  VCU_BeagleBone
 SG_ StatusPowerCoolingPumpRight : 24|4@1- (1,0) [0|0] ""  VCU_BeagleBone
 SG_ StatusPowerCoolingPumpLeft : 20|4@1- (1,0) [0|0] ""  VCU_BeagleBone
 SG_ StatusPowerCoolingFanRight : 12|4@1- (1,0) [0|0] ""  VCU_BeagleBone
 SG_ StatusPowerCoolingFanLeft : 8|4@1- (1,0) [0|0] ""  VCU_BeagleBone
 SG_ StatusPowerCoolingFanBattery : 4|4@1- (1,0) [0|0] ""  VCU_BeagleBone
 SG_ StatusPowerBMU : 0|4@1- (1,0) [0|0] ""  VCU_BeagleBone

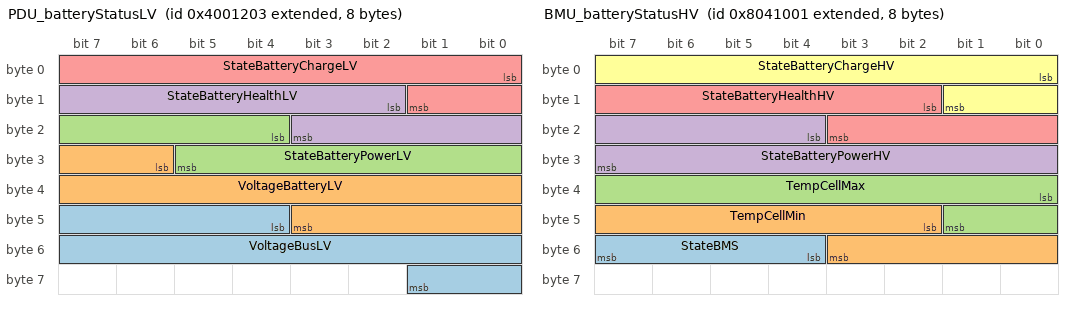
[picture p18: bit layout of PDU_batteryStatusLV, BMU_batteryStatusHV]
BO_ 2214597123 PDU_batteryStatusLV: 8 PDU
 SG_ VoltageBusLV : 44|14@1+ (1,0) [0|16383] "mV" Vector__XXX
 SG_ VoltageBatteryLV : 30|14@1+ (1,0) [0|16383] "mV" Vector__XXX
 SG_ StateBatteryPowerLV : 20|10@1+ (0.1,0) [0|100] "A"  VCU_BeagleBone
 SG_ StateBatteryHealthLV : 10|10@1+ (0.1,0) [0|100] "%"  VCU_BeagleBone
 SG_ StateBatteryChargeLV : 0|10@1+ (0.1,0) [0|102.3] "%"  VCU_BeagleBone

BO_ 2281967617 BMU_batteryStatusHV: 8 BMU
 SG_ StateBMS : 52|4@1- (1,0) [0|0] ""  VCU_F7
 SG_ TempCellMin : 42|10@1- (0.25,90) [-38|217.75] "C" Vector__XXX
 SG_ TempCellMax : 32|10@1- (0.25,90) [-38|217.75] "C" Vector__XXX
 SG_ StateBatteryPowerHV : 20|12@1+ (0.1,0) [0|409.5] "A"  VCU_BeagleBone,ChargeCart,DCU,VCU_F7
 SG_ StateBatteryHealthHV : 10|10@1+ (0.1,0) [0|100] "%"  VCU_BeagleBone,VCU_F7
 SG_ StateBatteryChargeHV : 0|10@1+ (0.1,0) [0|102.3] "%"  VCU_BeagleBone,DCU,VCU_F7

BO_ 2282754561 BMU_stateBusHV: 8 BMU
 SG_ CurrentBusHV : 48|16@1+ (0.01,0) [0|0] "A" Vector__XXX
 SG_ VoltageCellMin : 32|16@1+ (0.0001,0) [0|0] "V" Vector__XXX
 SG_ VoltageCellMax : 16|16@1+ (0.0001,0) [0|0] "V" Vector__XXX
 SG_ VoltageBusHV : 0|16@1+ (0.01,0) [0|0] "V"  VCU_BeagleBone,VCU_F7

BO_ 2214596611 PDU_DCDC_Status: 8 PDU
 SG_ Status_DCDC : 12|4@1- (1,0) [0|0] ""  VCU_BeagleBone,BMU
 SG_ CurrentOutputDCDC : 0|12@1+ (0.01220703125,0) [0|60] "Amps"  VCU_BeagleBone

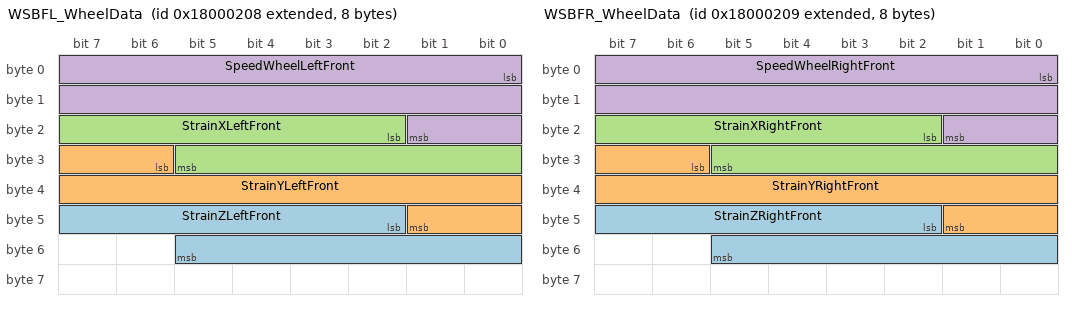
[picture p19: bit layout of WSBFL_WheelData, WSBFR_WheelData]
BO_ 2550137352 WSBFL_WheelData: 8 WSBFL
 SG_ StrainZLeftFront : 42|12@1+ (1,0) [0|0] "raw"  VCU_BeagleBone
 SG_ StrainYLeftFront : 30|12@1+ (1,0) [0|0] "raw"  VCU_BeagleBone
 SG_ StrainXLeftFront : 18|12@1+ (1,0) [0|0] "raw"  VCU_BeagleBone
 SG_ SpeedWheelLeftFront : 0|18@1- (0.00068664812716723,60) [-30.0003433240632|149.999656675936] "rad/s"  VCU_BeagleBone,VCU_F7

BO_ 2550137353 WSBFR_WheelData: 8 WSBFR
 SG_ StrainZRightFront : 42|12@1+ (1,0) [0|0] "raw"  VCU_BeagleBone
 SG_ StrainYRightFront : 30|12@1+ (1,0) [0|0] "raw"  VCU_BeagleBone
 SG_ StrainXRightFront : 18|12@1+ (1,0) [0|0] "raw"  VCU_BeagleBone
 SG_ SpeedWheelRightFront : 0|18@1- (0.00068664812716723,60) [-30.0003433240632|149.999656675936] "rad/s"  VCU_BeagleBone,VCU_F7

BO_TX_BU_ 2214986495 : BMU,ChargeCart,DCU,MCLeft,MCRight,VCU_F7,WSBFL,WSBFR,WSBRL,WSBRR,PDU;
BO_TX_BU_ 2298416383 : BMU,DCU,PDU,VCU_BeagleBone,WSBFL,WSBFR,WSBRL,WSBRR,VCU_F7;

CM_ BU_ MCLeft "5_2_Left Inverter";
CM_ BU_ MCRight "6_2_Right Inverter";
CM_ BU_ DCU "7_3_Driver Contol Unit";
CM_ BU_ PDU "3__Power Distribution Unit";
CM_ BU_ BMU "1_1_Battery Managment Unit";
CM_ BU_ VCU_F7 "2_1_Vehicle Control Unit";
CM_ BU_ WSBFL "8_4_Wheel Sensor Board Front Left";
CM_ BU_ WSBFR "9_4_Wheel Sensor Board Front Right";
CM_ BU_ WSBRL "10_4_Wheel Sensor Board Rear Left";
CM_ BU_ WSBRR "11_4_Wheel Sensor Board Rear Right";
CM_ BU_ ChargeCart "4_3_Charge Cart PCB";
CM_ BO_ 3221225472 "This is a message for not used signals, created by Vector CANdb++ DBC OLE DB Provider.";
CM_ SG_ 3221225472 PRO_CAN_CRC "PROCANPROCAN";
CM_ SG_ 3221225472 PRO_CAN_COUNT "PROCANPROCAN";
CM_ SG_ 3221225472 PRO_CAN_RES "PROCANPROCAN";
CM_ BO_ 2550141444 "VERSION";
CM_ BO_ 2550141441 "VERSION";
CM_ BO_ 2550136839 "VERSION";
CM_ BO_ 2550141443 "VERSION";
CM_ BO_ 2550141442 "VERSION";
CM_ BO_ 2240413554 "PROCAN";
CM_ SG_ 2240413554 PRO_CAN_CRC "PROCAN";
CM_ SG_ 2240413554 PRO_CAN_COUNT "PROCAN";
CM_ SG_ 2240413554 PRO_CAN_RES "PROCAN";
CM_ BO_ 2240348018 "PROCAN";
CM_ SG_ 2240348018 PRO_CAN_CRC "PROCAN";
CM_ SG_ 2240348018 PRO_CAN_COUNT "PROCAN";
CM_ SG_ 2240348018 PRO_CAN_RES "PROCAN";
CM_ BO_ 2240216946 "PROCAN";
CM_ SG_ 2240216946 PRO_CAN_CRC "PROCAN";
CM_ SG_ 2240216946 PRO_CAN_COUNT "PROCAN";
CM_ SG_ 2240216946 PRO_CAN_RES "PROCAN";
CM_ BO_ 2550137350 "PROCAN";
CM_ SG_ 2550137350 PRO_CAN_RES "PROCAN";
CM_ SG_ 2550137350 PRO_CAN_CRC "PROCAN";
CM_ SG_ 2550137350 PRO_CAN_COUNT "PROCAN";
CM_ BO_ 2239984130 "PROCAN";
CM_ SG_ 2239984130 PRO_CAN_CRC "PROCAN";
CM_ SG_ 2239984130 PRO_CAN_COUNT "PROCAN";
CM_ SG_ 2239984130 PRO_CAN_RES "PROCAN";
CM_ BO_ 2239918594 "PROCAN";
CM_ SG_ 2239918594 PRO_CAN_CRC "PROCAN";
CM_ SG_ 2239918594 PRO_CAN_COUNT "PROCAN";
CM_ SG_ 2239918594 PRO_CAN_RES "PROCAN";
CM_ BO_ 2239853058 "PROCAN";
CM_ SG_ 2239853058 PRO_CAN_CRC "PROCAN";
CM_ SG_ 2239853058 PRO_CAN_COUNT "PROCAN";
CM_ SG_ 2239853058 PRO_CAN_RES "PROCAN";
CM_ BO_ 2239787522 "PROCAN";
CM_ SG_ 2239787522 PRO_CAN_CRC "PROCAN";
CM_ SG_ 2239787522 PRO_CAN_COUNT "PROCAN";
CM_ SG_ 2239787522 PRO_CAN_RES "PROCAN";
CM_ BO_ 2241462129 "PROCAN";
CM_ SG_ 2241462129 PRO_CAN_CRC "PROCAN";
CM_ SG_ 2241462129 PRO_CAN_COUNT "PROCAN";
CM_ SG_ 2241462129 PRO_CAN_RES "PROCAN";
CM_ BO_ 2241396593 "PROCAN";
CM_ SG_ 2241396593 PRO_CAN_CRC "PROCAN";
CM_ SG_ 2241396593 PRO_CAN_COUNT "PROCAN";
CM_ SG_ 2241396593 PRO_CAN_RES "PROCAN";
CM_ BO_ 2241265521 "PROCAN";
CM_ SG_ 2241265521 PRO_CAN_CRC "PROCAN";
CM_ SG_ 2241265521 PRO_CAN_COUNT "PROCAN";
CM_ SG_ 2241265521 PRO_CAN_RES "PROCAN";
CM_ BO_ 2550137349 "PROCAN";
CM_ SG_ 2550137349 PRO_CAN_RES "PROCAN";
CM_ SG_ 2550137349 PRO_CAN_CRC "PROCAN";
CM_ SG_ 2550137349 PRO_CAN_COUNT "PROCAN";
CM_ BO_ 2241032450 "PROCAN";
CM_ SG_ 2241032450 PRO_CAN_CRC "PROCAN";
CM_ SG_ 2241032450 PRO_CAN_COUNT "PROCAN";
CM_ SG_ 2241032450 PRO_CAN_RES "PROCAN";
CM_ BO_ 2240966914 "PROCAN";
CM_ SG_ 2240966914 PRO_CAN_CRC "PROCAN";
CM_ SG_ 2240966914 PRO_CAN_COUNT "PROCAN";
CM_ SG_ 2240966914 PRO_CAN_RES "PROCAN";
CM_ BO_ 2240901378 "PROCAN";
CM_ SG_ 2240901378 PRO_CAN_CRC "PROCAN";
CM_ SG_ 2240901378 PRO_CAN_COUNT "PROCAN";
CM_ SG_ 2240901378 PRO_CAN_RES "PROCAN";
CM_ BO_ 2240835842 "PROCAN";
CM_ SG_ 2240835842 PRO_CAN_CRC "PROCAN";
CM_ SG_ 2240835842 PRO_CAN_COUNT "PROCAN";
CM_ SG_ 2240835842 PRO_CAN_RES "PROCAN";
BA_DEF_  "BusType" STRING ;
BA_DEF_DEF_  "BusType" "CAN";
VAL_ 3221225472 StateContactorPositive 4 "CONTACTOR_FAULT_CLOSED" 3 "CONTACTOR_FAULT_OPEN" 2 "CONTACTOR_CLOSED" 1 "CONTACTOR_OPEN" 0 "INVALID" ;
VAL_ 3221225472 StateContactorNegative 4 "CONTACTOR_FAULT_CLOSED" 3 "CONTACTOR_FAULT_OPEN" 2 "CONTACTOR_CLOSED" 1 "CONTACTOR_OPEN" 0 "INVALID" ;
VAL_ 2226717697 ChargeEN_State 1 "On" 0 "Off" ;
VAL_ 2214987522 EM_State 1 "On" 0 "Off" ;
VAL_ 2217082625 HV_Power_State 1 "On" 0 "Off" ;
VAL_ 2214855426 EM_Power_State_Request 1 "On" 0 "Off" ;
VAL_ 2214986243 StatusPowerVCU 4 "CHANNEL_ON_FUSE_BLOWN" 3 "CHANNEL_OFF_FUSE_BLOWN" 2 "CHANNEL_ON" 1 "CHANNEL_OFF" 0 "INVALID" ;
VAL_ 2214986243 StatusPowerMCRight 4 "CHANNEL_ON_FUSE_BLOWN" 3 "CHANNEL_OFF_FUSE_BLOWN" 2 "CHANNEL_ON" 1 "CHANNEL_OFF" 0 "INVALID" ;
VAL_ 2214986243 StatusPowerMCLeft 4 "CHANNEL_ON_FUSE_BLOWN" 3 "CHANNEL_OFF_FUSE_BLOWN" 2 "CHANNEL_ON" 1 "CHANNEL_OFF" 0 "INVALID" ;
VAL_ 2214986243 StatusPowerIMD 4 "CHANNEL_ON_FUSE_BLOWN" 3 "CHANNEL_OFF_FUSE_BLOWN" 2 "CHANNEL_ON" 1 "CHANNEL_OFF" 0 "INVALID" ;
VAL_ 2214986243 StatusPowerDCU 4 "CHANNEL_ON_FUSE_BLOWN" 3 "CHANNEL_OFF_FUSE_BLOWN" 2 "CHANNEL_ON" 1 "CHANNEL_OFF" 0 "INVALID" ;
VAL_ 2214986243 StatusPowerDAU 4 "CHANNEL_ON_FUSE_BLOWN" 3 "CHANNEL_OFF_FUSE_BLOWN" 2 "CHANNEL_ON" 1 "CHANNEL_OFF" 0 "INVALID" ;
VAL_ 2214986243 StatusPowerCoolingPumpRight 4 "CHANNEL_ON_FUSE_BLOWN" 3 "CHANNEL_OFF_FUSE_BLOWN" 2 "CHANNEL_ON" 1 "CHANNEL_OFF" 0 "INVALID" ;
VAL_ 2214986243 StatusPowerCoolingPumpLeft 4 "CHANNEL_ON_FUSE_BLOWN" 3 "CHANNEL_OFF_FUSE_BLOWN" 2 "CHANNEL_ON" 1 "CHANNEL_OFF" 0 "INVALID" ;
VAL_ 2214986243 StatusPowerCoolingFanRight 4 "CHANNEL_ON_FUSE_BLOWN" 3 "CHANNEL_OFF_FUSE_BLOWN" 2 "CHANNEL_ON" 1 "CHANNEL_OFF" 0 "INVALID" ;
VAL_ 2214986243 StatusPowerCoolingFanLeft 4 "CHANNEL_ON_FUSE_BLOWN" 3 "CHANNEL_OFF_FUSE_BLOWN" 2 "CHANNEL_ON" 1 "CHANNEL_OFF" 0 "INVALID" ;
VAL_ 2214986243 StatusPowerCoolingFanBattery 4 "CHANNEL_ON_FUSE_BLOWN" 3 "CHANNEL_OFF_FUSE_BLOWN" 2 "CHANNEL_ON" 1 "CHANNEL_OFF" 0 "INVALID" ;
VAL_ 2214986243 StatusPowerBMU 4 "CHANNEL_ON_FUSE_BLOWN" 3 "CHANNEL_OFF_FUSE_BLOWN" 2 "CHANNEL_ON" 1 "CHANNEL_OFF" 0 "INVALID" ;
VAL_ 2281967617 StateBMS 7 "Failure_Fatal" 6 "Charging" 5 "Discharge" 4 "Precharge" 3 "HV_Enable" 2 "HV_Disable" 1 "Wait_System_Up" 0 "Self_Check" ;
VAL_ 2214596611 Status_DCDC 3 "Error" 2 "On" 1 "Off" 0 "Invalid" ;
